AUTOSAR XML (schema 3.1.2)
package /Components/SWC_EngMGslT
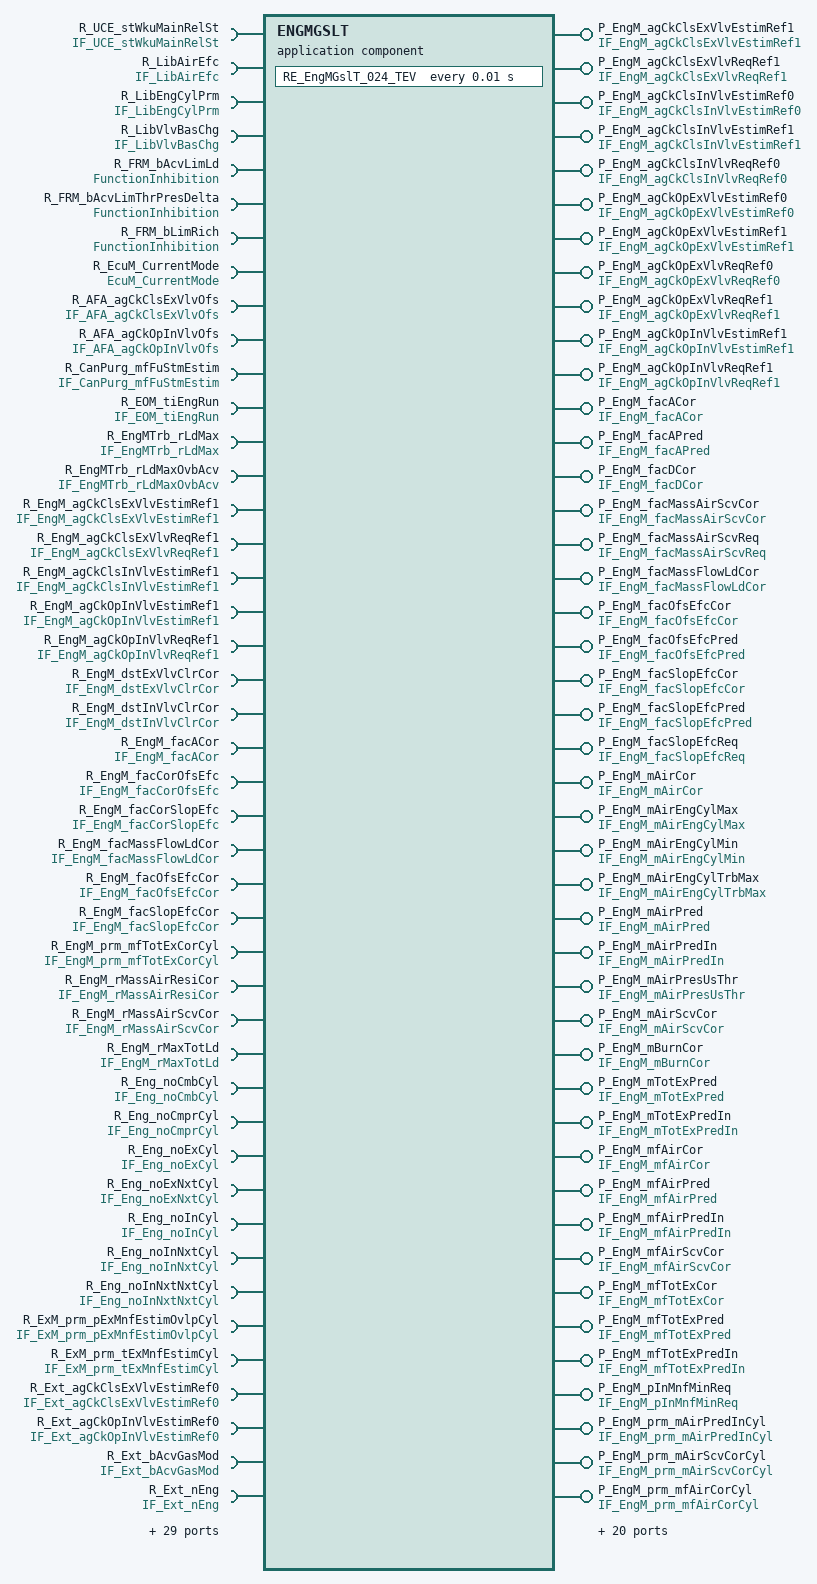
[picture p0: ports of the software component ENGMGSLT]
  application software component type ENGMGSLT  # EngMGslT
    7 x require port:
      R_UCE_stWkuMainRelSt: required-interface=IF_UCE_stWkuMainRelSt
      R_LibAirEfc: required-interface=IF_LibAirEfc
      R_LibEngCylPrm: required-interface=IF_LibEngCylPrm
      R_LibVlvBasChg: required-interface=IF_LibVlvBasChg
      R_FRM_bAcvLimLd: required-interface=FunctionInhibition
      R_FRM_bAcvLimThrPresDelta: required-interface=FunctionInhibition
      R_FRM_bLimRich: required-interface=FunctionInhibition
    63 x provide port:
      P_EngM_agCkClsExVlvEstimRef1: unqueued-sender-com-spec{data-element=EngM_agCkClsExVlvEstimRef1, can-invalidate=false, init-value=ConstantValue}, provided-interface=IF_EngM_agCkClsExVlvEstimRef1
      P_EngM_agCkClsExVlvReqRef1: unqueued-sender-com-spec{data-element=EngM_agCkClsExVlvReqRef1, can-invalidate=false, init-value=SInt16InitValue}, provided-interface=IF_EngM_agCkClsExVlvReqRef1
      P_EngM_agCkClsInVlvEstimRef0: unqueued-sender-com-spec{data-element=EngM_agCkClsInVlvEstimRef0, can-invalidate=false, init-value=UInt16InitValue}, provided-interface=IF_EngM_agCkClsInVlvEstimRef0
      P_EngM_agCkClsInVlvEstimRef1: unqueued-sender-com-spec{data-element=EngM_agCkClsInVlvEstimRef1, can-invalidate=false, init-value=ConstantValue1}, provided-interface=IF_EngM_agCkClsInVlvEstimRef1
      P_EngM_agCkClsInVlvReqRef0: unqueued-sender-com-spec{data-element=EngM_agCkClsInVlvReqRef0, can-invalidate=false, init-value=UInt8InitValue}, provided-interface=IF_EngM_agCkClsInVlvReqRef0
      P_EngM_agCkOpExVlvEstimRef0: unqueued-sender-com-spec{data-element=EngM_agCkOpExVlvEstimRef0, can-invalidate=false, init-value=UInt16InitValue3}, provided-interface=IF_EngM_agCkOpExVlvEstimRef0
      P_EngM_agCkOpExVlvEstimRef1: unqueued-sender-com-spec{data-element=EngM_agCkOpExVlvEstimRef1, can-invalidate=false, init-value=UInt16InitValue5}, provided-interface=IF_EngM_agCkOpExVlvEstimRef1
      P_EngM_agCkOpExVlvReqRef0: unqueued-sender-com-spec{data-element=EngM_agCkOpExVlvReqRef0, can-invalidate=false, init-value=UInt8InitValue7}, provided-interface=IF_EngM_agCkOpExVlvReqRef0
      P_EngM_agCkOpExVlvReqRef1: unqueued-sender-com-spec{data-element=EngM_agCkOpExVlvReqRef1, can-invalidate=false, init-value=UInt8InitValue9}, provided-interface=IF_EngM_agCkOpExVlvReqRef1
      P_EngM_agCkOpInVlvEstimRef1: unqueued-sender-com-spec{data-element=EngM_agCkOpInVlvEstimRef1, can-invalidate=false, init-value=ConstantValue11}, provided-interface=IF_EngM_agCkOpInVlvEstimRef1
      P_EngM_agCkOpInVlvReqRef1: unqueued-sender-com-spec{data-element=EngM_agCkOpInVlvReqRef1, can-invalidate=false, init-value=SInt16InitValue13}, provided-interface=IF_EngM_agCkOpInVlvReqRef1
      P_EngM_facACor: unqueued-sender-com-spec{data-element=EngM_facACor, can-invalidate=false, init-value=ConstantValue15}, provided-interface=IF_EngM_facACor
      P_EngM_facAPred: unqueued-sender-com-spec{data-element=EngM_facAPred, can-invalidate=false, init-value=UInt8InitValue17}, provided-interface=IF_EngM_facAPred
      P_EngM_facDCor: unqueued-sender-com-spec{data-element=EngM_facDCor, can-invalidate=false, init-value=UInt8InitValue19}, provided-interface=IF_EngM_facDCor
      P_EngM_facMassAirScvCor: unqueued-sender-com-spec{data-element=EngM_facMassAirScvCor, can-invalidate=false, init-value=UInt32InitValue}, provided-interface=IF_EngM_facMassAirScvCor
      P_EngM_facMassAirScvReq: unqueued-sender-com-spec{data-element=EngM_facMassAirScvReq, can-invalidate=false, init-value=UInt32InitValue21}, provided-interface=IF_EngM_facMassAirScvReq
      P_EngM_facMassFlowLdCor: unqueued-sender-com-spec{data-element=EngM_facMassFlowLdCor, can-invalidate=false, init-value=UInt16InitValue23}, provided-interface=IF_EngM_facMassFlowLdCor
      P_EngM_facOfsEfcCor: unqueued-sender-com-spec{data-element=EngM_facOfsEfcCor, can-invalidate=false, init-value=ConstantValue25}, provided-interface=IF_EngM_facOfsEfcCor
      P_EngM_facOfsEfcPred: unqueued-sender-com-spec{data-element=EngM_facOfsEfcPred, can-invalidate=false, init-value=UInt16InitValue27}, provided-interface=IF_EngM_facOfsEfcPred
      P_EngM_facSlopEfcCor: unqueued-sender-com-spec{data-element=EngM_facSlopEfcCor, can-invalidate=false, init-value=ConstantValue29}, provided-interface=IF_EngM_facSlopEfcCor
      P_EngM_facSlopEfcPred: unqueued-sender-com-spec{data-element=EngM_facSlopEfcPred, can-invalidate=false, init-value=UInt16InitValue31}, provided-interface=IF_EngM_facSlopEfcPred
      P_EngM_facSlopEfcReq: unqueued-sender-com-spec{data-element=EngM_facSlopEfcReq, can-invalidate=false, init-value=ConstantValue33}, provided-interface=IF_EngM_facSlopEfcReq
      P_EngM_mAirCor: unqueued-sender-com-spec{data-element=EngM_mAirCor, can-invalidate=false, init-value=ConstantValue35}, provided-interface=IF_EngM_mAirCor
      P_EngM_mAirEngCylMax: unqueued-sender-com-spec{data-element=EngM_mAirEngCylMax, can-invalidate=false, init-value=ConstantValue37}, provided-interface=IF_EngM_mAirEngCylMax
      P_EngM_mAirEngCylMin: unqueued-sender-com-spec{data-element=EngM_mAirEngCylMin, can-invalidate=false, init-value=ConstantValue39}, provided-interface=IF_EngM_mAirEngCylMin
      P_EngM_mAirEngCylTrbMax: unqueued-sender-com-spec{data-element=EngM_mAirEngCylTrbMax, can-invalidate=false, init-value=ConstantValue41}, provided-interface=IF_EngM_mAirEngCylTrbMax
      P_EngM_mAirPred: unqueued-sender-com-spec{data-element=EngM_mAirPred, can-invalidate=false, init-value=UInt16InitValue43}, provided-interface=IF_EngM_mAirPred
      P_EngM_mAirPredIn: unqueued-sender-com-spec{data-element=EngM_mAirPredIn, can-invalidate=false, init-value=UInt16InitValue45}, provided-interface=IF_EngM_mAirPredIn
      P_EngM_mAirPresUsThr: unqueued-sender-com-spec{data-element=EngM_mAirPresUsThr, can-invalidate=false, init-value=ConstantValue47}, provided-interface=IF_EngM_mAirPresUsThr
      P_EngM_mAirScvCor: unqueued-sender-com-spec{data-element=EngM_mAirScvCor, can-invalidate=false, init-value=UInt16InitValue49}, provided-interface=IF_EngM_mAirScvCor
      P_EngM_mBurnCor: unqueued-sender-com-spec{data-element=EngM_mBurnCor, can-invalidate=false, init-value=ConstantValue51}, provided-interface=IF_EngM_mBurnCor
      P_EngM_mTotExPred: unqueued-sender-com-spec{data-element=EngM_mTotExPred, can-invalidate=false, init-value=UInt16InitValue53}, provided-interface=IF_EngM_mTotExPred
      P_EngM_mTotExPredIn: unqueued-sender-com-spec{data-element=EngM_mTotExPredIn, can-invalidate=false, init-value=UInt16InitValue55}, provided-interface=IF_EngM_mTotExPredIn
      P_EngM_mfAirCor: unqueued-sender-com-spec{data-element=EngM_mfAirCor, can-invalidate=false, init-value=UInt16InitValue57}, provided-interface=IF_EngM_mfAirCor
      P_EngM_mfAirPred: unqueued-sender-com-spec{data-element=EngM_mfAirPred, can-invalidate=false, init-value=UInt16InitValue59}, provided-interface=IF_EngM_mfAirPred
      P_EngM_mfAirPredIn: unqueued-sender-com-spec{data-element=EngM_mfAirPredIn, can-invalidate=false, init-value=UInt16InitValue61}, provided-interface=IF_EngM_mfAirPredIn
      P_EngM_mfAirScvCor: unqueued-sender-com-spec{data-element=EngM_mfAirScvCor, can-invalidate=false, init-value=ConstantValue63}, provided-interface=IF_EngM_mfAirScvCor
      P_EngM_mfTotExCor: unqueued-sender-com-spec{data-element=EngM_mfTotExCor, can-invalidate=false, init-value=UInt16InitValue65}, provided-interface=IF_EngM_mfTotExCor
      P_EngM_mfTotExPred: unqueued-sender-com-spec{data-element=EngM_mfTotExPred, can-invalidate=false, init-value=UInt16InitValue67}, provided-interface=IF_EngM_mfTotExPred
      P_EngM_mfTotExPredIn: unqueued-sender-com-spec{data-element=EngM_mfTotExPredIn, can-invalidate=false, init-value=UInt16InitValue69}, provided-interface=IF_EngM_mfTotExPredIn
      P_EngM_pInMnfMinReq: unqueued-sender-com-spec{data-element=EngM_pInMnfMinReq, can-invalidate=false, init-value=UInt16InitValue71}, provided-interface=IF_EngM_pInMnfMinReq
      P_EngM_prm_mAirPredInCyl: unqueued-sender-com-spec{data-element=EngM_prm_mAirPredInCyl, can-invalidate=false, init-value=rt_Array_UInt16_6InitValue}, provided-interface=IF_EngM_prm_mAirPredInCyl
      P_EngM_prm_mAirScvCorCyl: unqueued-sender-com-spec{data-element=EngM_prm_mAirScvCorCyl, can-invalidate=false, init-value=rt_Array_UInt16_6InitValue73}, provided-interface=IF_EngM_prm_mAirScvCorCyl
      P_EngM_prm_mfAirCorCyl: unqueued-sender-com-spec{data-element=EngM_prm_mfAirCorCyl, can-invalidate=false, init-value=rt_Array_UInt16_6InitValue75}, provided-interface=IF_EngM_prm_mfAirCorCyl
      P_EngM_prm_mfAirPredInCyl: unqueued-sender-com-spec{data-element=EngM_prm_mfAirPredInCyl, can-invalidate=false, init-value=rt_Array_UInt16_6InitValue77}, provided-interface=IF_EngM_prm_mfAirPredInCyl
      P_EngM_prm_mfAirScvCorCyl: unqueued-sender-com-spec{data-element=EngM_prm_mfAirScvCorCyl, can-invalidate=false, init-value=rt_Array_UInt16_6InitValue79}, provided-interface=IF_EngM_prm_mfAirScvCorCyl
      P_EngM_prm_mfTotExCorCyl: unqueued-sender-com-spec{data-element=EngM_prm_mfTotExCorCyl, can-invalidate=false, init-value=rt_Array_UInt16_6InitValue81}, provided-interface=IF_EngM_prm_mfTotExCorCyl
      P_EngM_prm_rAirLdPredInCyl: unqueued-sender-com-spec{data-element=EngM_prm_rAirLdPredInCyl, can-invalidate=false, init-value=rt_Array_UInt16_6InitValue83}, provided-interface=IF_EngM_prm_rAirLdPredInCyl
      P_EngM_prm_rTotLdExCorCyl: unqueued-sender-com-spec{data-element=EngM_prm_rTotLdExCorCyl, can-invalidate=false, init-value=rt_Array_UInt16_6InitValue85}, provided-interface=IF_EngM_prm_rTotLdExCorCyl
      P_EngM_rAirLdCor: unqueued-sender-com-spec{data-element=EngM_rAirLdCor, can-invalidate=false, init-value=ConstantValue87}, provided-interface=IF_EngM_rAirLdCor
      P_EngM_rAirLdPred: unqueued-sender-com-spec{data-element=EngM_rAirLdPred, can-invalidate=false, init-value=ConstantValue89}, provided-interface=IF_EngM_rAirLdPred
      P_EngM_rAirLdPredIn: unqueued-sender-com-spec{data-element=EngM_rAirLdPredIn, can-invalidate=false, init-value=UInt16InitValue91}, provided-interface=IF_EngM_rAirLdPredIn
      P_EngM_rDeltaLdInjPha: unqueued-sender-com-spec{data-element=EngM_rDeltaLdInjPha, can-invalidate=false, init-value=ConstantValue93}, provided-interface=IF_EngM_rDeltaLdInjPha
      P_EngM_rItBurnRateCor: unqueued-sender-com-spec{data-element=EngM_rItBurnRateCor, can-invalidate=false, init-value=ConstantValue95}, provided-interface=IF_EngM_rItBurnRateCor
      P_EngM_rMassAirResiCor: unqueued-sender-com-spec{data-element=EngM_rMassAirResiCor, can-invalidate=false, init-value=ConstantValue97}, provided-interface=IF_EngM_rMassAirResiCor
      P_EngM_rMassAirScvCor: unqueued-sender-com-spec{data-element=EngM_rMassAirScvCor, can-invalidate=false, init-value=ConstantValue99}, provided-interface=IF_EngM_rMassAirScvCor
      P_EngM_rMaxTotLd: unqueued-sender-com-spec{data-element=EngM_rMaxTotLd, can-invalidate=false, init-value=ConstantValue101}, provided-interface=IF_EngM_rMaxTotLd
      P_EngM_rTotLdExCor: unqueued-sender-com-spec{data-element=EngM_rTotLdExCor, can-invalidate=false, init-value=ConstantValue103}, provided-interface=IF_EngM_rTotLdExCor
      P_EngM_rTotLdExPred: unqueued-sender-com-spec{data-element=EngM_rTotLdExPred, can-invalidate=false, init-value=UInt16InitValue105}, provided-interface=IF_EngM_rTotLdExPred
      P_EngM_rltMassAirScvCor: unqueued-sender-com-spec{data-element=EngM_rltMassAirScvCor, can-invalidate=false, init-value=ConstantValue107}, provided-interface=IF_EngM_rltMassAirScvCor
      P_EngM_tBurnCylCor: unqueued-sender-com-spec{data-element=EngM_tBurnCylCor, can-invalidate=false, init-value=UInt16InitValue109}, provided-interface=IF_EngM_tBurnCylCor
      P_EngM_tMixtCylCor: unqueued-sender-com-spec{data-element=EngM_tMixtCylCor, can-invalidate=false, init-value=ConstantValue111}, provided-interface=IF_EngM_tMixtCylCor
      P_EngM_tMixtCylGDICor: unqueued-sender-com-spec{data-element=EngM_tMixtCylGDICor, can-invalidate=false, init-value=UInt16InitValue113}, provided-interface=IF_EngM_tMixtCylGDICor
    65 x require port:
      R_EcuM_CurrentMode: required-interface=EcuM_CurrentMode
      R_AFA_agCkClsExVlvOfs: unqueued-receiver-com-spec{data-element=AFA_agCkClsExVlvOfs, init-value=ConstantValue115, resync-time=0}, required-interface=IF_AFA_agCkClsExVlvOfs
      R_AFA_agCkOpInVlvOfs: unqueued-receiver-com-spec{data-element=AFA_agCkOpInVlvOfs, init-value=ConstantValue117, resync-time=0}, required-interface=IF_AFA_agCkOpInVlvOfs
      R_CanPurg_mfFuStmEstim: unqueued-receiver-com-spec{data-element=CanPurg_mfFuStmEstim, init-value=ConstantValue119, resync-time=0}, required-interface=IF_CanPurg_mfFuStmEstim
      R_EOM_tiEngRun: unqueued-receiver-com-spec{data-element=EOM_tiEngRun, init-value=ConstantValue121, resync-time=0}, required-interface=IF_EOM_tiEngRun
      R_EngMTrb_rLdMax: unqueued-receiver-com-spec{data-element=EngMTrb_rLdMax, init-value=ConstantValue123, resync-time=0}, required-interface=IF_EngMTrb_rLdMax
      R_EngMTrb_rLdMaxOvbAcv: unqueued-receiver-com-spec{data-element=EngMTrb_rLdMaxOvbAcv, init-value=ConstantValue125, resync-time=0}, required-interface=IF_EngMTrb_rLdMaxOvbAcv
      R_EngM_agCkClsExVlvEstimRef1: unqueued-receiver-com-spec{data-element=EngM_agCkClsExVlvEstimRef1, init-value=ConstantValue, resync-time=0}, required-interface=IF_EngM_agCkClsExVlvEstimRef1
      R_EngM_agCkClsExVlvReqRef1: unqueued-receiver-com-spec{data-element=EngM_agCkClsExVlvReqRef1, init-value=SInt16InitValue, resync-time=0}, required-interface=IF_EngM_agCkClsExVlvReqRef1
      R_EngM_agCkClsInVlvEstimRef1: unqueued-receiver-com-spec{data-element=EngM_agCkClsInVlvEstimRef1, init-value=ConstantValue127, resync-time=0}, required-interface=IF_EngM_agCkClsInVlvEstimRef1
      R_EngM_agCkOpInVlvEstimRef1: unqueued-receiver-com-spec{data-element=EngM_agCkOpInVlvEstimRef1, init-value=ConstantValue129, resync-time=0}, required-interface=IF_EngM_agCkOpInVlvEstimRef1
      R_EngM_agCkOpInVlvReqRef1: unqueued-receiver-com-spec{data-element=EngM_agCkOpInVlvReqRef1, init-value=SInt16InitValue131, resync-time=0}, required-interface=IF_EngM_agCkOpInVlvReqRef1
      R_EngM_dstExVlvClrCor: unqueued-receiver-com-spec{data-element=EngM_dstExVlvClrCor, init-value=UInt16InitValue133, resync-time=0}, required-interface=IF_EngM_dstExVlvClrCor
      R_EngM_dstInVlvClrCor: unqueued-receiver-com-spec{data-element=EngM_dstInVlvClrCor, init-value=UInt16InitValue135, resync-time=0}, required-interface=IF_EngM_dstInVlvClrCor
      R_EngM_facACor: unqueued-receiver-com-spec{data-element=EngM_facACor, init-value=ConstantValue137, resync-time=0}, required-interface=IF_EngM_facACor
      R_EngM_facCorOfsEfc: unqueued-receiver-com-spec{data-element=EngM_facCorOfsEfc, init-value=SInt16InitValue139, resync-time=0}, required-interface=IF_EngM_facCorOfsEfc
      R_EngM_facCorSlopEfc: unqueued-receiver-com-spec{data-element=EngM_facCorSlopEfc, init-value=UInt16InitValue141, resync-time=0}, required-interface=IF_EngM_facCorSlopEfc
      R_EngM_facMassFlowLdCor: unqueued-receiver-com-spec{data-element=EngM_facMassFlowLdCor, init-value=UInt16InitValue143, resync-time=0}, required-interface=IF_EngM_facMassFlowLdCor
      R_EngM_facOfsEfcCor: unqueued-receiver-com-spec{data-element=EngM_facOfsEfcCor, init-value=ConstantValue145, resync-time=0}, required-interface=IF_EngM_facOfsEfcCor
      R_EngM_facSlopEfcCor: unqueued-receiver-com-spec{data-element=EngM_facSlopEfcCor, init-value=ConstantValue147, resync-time=0}, required-interface=IF_EngM_facSlopEfcCor
      R_EngM_prm_mfTotExCorCyl: unqueued-receiver-com-spec{data-element=EngM_prm_mfTotExCorCyl, init-value=rt_Array_UInt16_6InitValue149, resync-time=0}, required-interface=IF_EngM_prm_mfTotExCorCyl
      R_EngM_rMassAirResiCor: unqueued-receiver-com-spec{data-element=EngM_rMassAirResiCor, init-value=ConstantValue151, resync-time=0}, required-interface=IF_EngM_rMassAirResiCor
      R_EngM_rMassAirScvCor: unqueued-receiver-com-spec{data-element=EngM_rMassAirScvCor, init-value=ConstantValue153, resync-time=0}, required-interface=IF_EngM_rMassAirScvCor
      R_EngM_rMaxTotLd: unqueued-receiver-com-spec{data-element=EngM_rMaxTotLd, init-value=ConstantValue155, resync-time=0}, required-interface=IF_EngM_rMaxTotLd
      R_Eng_noCmbCyl: unqueued-receiver-com-spec{data-element=Eng_noCmbCyl, init-value=UInt8InitValue157, resync-time=0}, required-interface=IF_Eng_noCmbCyl
      R_Eng_noCmprCyl: unqueued-receiver-com-spec{data-element=Eng_noCmprCyl, init-value=ConstantValue159, resync-time=0}, required-interface=IF_Eng_noCmprCyl
      R_Eng_noExCyl: unqueued-receiver-com-spec{data-element=Eng_noExCyl, init-value=UInt8InitValue161, resync-time=0}, required-interface=IF_Eng_noExCyl
      R_Eng_noExNxtCyl: unqueued-receiver-com-spec{data-element=Eng_noExNxtCyl, init-value=UInt8InitValue163, resync-time=0}, required-interface=IF_Eng_noExNxtCyl
      R_Eng_noInCyl: unqueued-receiver-com-spec{data-element=Eng_noInCyl, init-value=UInt8InitValue165, resync-time=0}, required-interface=IF_Eng_noInCyl
      R_Eng_noInNxtCyl: unqueued-receiver-com-spec{data-element=Eng_noInNxtCyl, init-value=UInt8InitValue167, resync-time=0}, required-interface=IF_Eng_noInNxtCyl
      R_Eng_noInNxtNxtCyl: unqueued-receiver-com-spec{data-element=Eng_noInNxtNxtCyl, init-value=UInt8InitValue169, resync-time=0}, required-interface=IF_Eng_noInNxtNxtCyl
      R_ExM_prm_pExMnfEstimOvlpCyl: unqueued-receiver-com-spec{data-element=ExM_prm_pExMnfEstimOvlpCyl, init-value=rt_Array_UInt16_6InitValue171, resync-time=0}, required-interface=IF_ExM_prm_pExMnfEstimOvlpCyl
      R_ExM_prm_tExMnfEstimCyl: unqueued-receiver-com-spec{data-element=ExM_prm_tExMnfEstimCyl, init-value=rt_Array_UInt16_6InitValue173, resync-time=0}, required-interface=IF_ExM_prm_tExMnfEstimCyl
      R_Ext_agCkClsExVlvEstimRef0: unqueued-receiver-com-spec{data-element=Ext_agCkClsExVlvEstimRef0, init-value=ConstantValue175, resync-time=0}, required-interface=IF_Ext_agCkClsExVlvEstimRef0
      R_Ext_agCkOpInVlvEstimRef0: unqueued-receiver-com-spec{data-element=Ext_agCkOpInVlvEstimRef0, init-value=ConstantValue177, resync-time=0}, required-interface=IF_Ext_agCkOpInVlvEstimRef0
      R_Ext_bAcvGasMod: unqueued-receiver-com-spec{data-element=Ext_bAcvGasMod, init-value=BooleanInitValue, resync-time=0}, required-interface=IF_Ext_bAcvGasMod
      R_Ext_nEng: unqueued-receiver-com-spec{data-element=Ext_nEng, init-value=ConstantValue179, resync-time=0}, required-interface=IF_Ext_nEng
      R_Ext_pFuMesFineResl: unqueued-receiver-com-spec{data-element=Ext_pFuMesFineResl, init-value=UInt16InitValue181, resync-time=0}, required-interface=IF_Ext_pFuMesFineResl
      R_Ext_tCoMes: unqueued-receiver-com-spec{data-element=Ext_tCoMes, init-value=ConstantValue183, resync-time=0}, required-interface=IF_Ext_tCoMes
      R_Ext_tCoStrtMes: unqueued-receiver-com-spec{data-element=Ext_tCoStrtMes, init-value=ConstantValue185, resync-time=0}, required-interface=IF_Ext_tCoStrtMes
      R_FARSp_rMixtCylSp: unqueued-receiver-com-spec{data-element=FARSp_rMixtCylSp, init-value=ConstantValue187, resync-time=0}, required-interface=IF_FARSp_rMixtCylSp
      R_FuSysM_tFu: unqueued-receiver-com-spec{data-element=FuSysM_tFu, init-value=UInt16InitValue189, resync-time=0}, required-interface=IF_FuSysM_tFu
      R_InM_concAirCor: unqueued-receiver-com-spec{data-element=InM_concAirCor, init-value=ConstantValue191, resync-time=0}, required-interface=IF_InM_concAirCor
      R_InM_pDsThrCor: unqueued-receiver-com-spec{data-element=InM_pDsThrCor, init-value=ConstantValue193, resync-time=0}, required-interface=IF_InM_pDsThrCor
      R_InM_prm_concAirPredCyl: unqueued-receiver-com-spec{data-element=InM_prm_concAirPredCyl, init-value=rt_Array_UInt16_6InitValue195, resync-time=0}, required-interface=IF_InM_prm_concAirPredCyl
      R_InM_prm_pDsThrPredCyl: unqueued-receiver-com-spec{data-element=InM_prm_pDsThrPredCyl, init-value=rt_Array_UInt16_6InitValue197, resync-time=0}, required-interface=IF_InM_prm_pDsThrPredCyl
      R_InM_prm_pDsThrPredOvlpCyl: unqueued-receiver-com-spec{data-element=InM_prm_pDsThrPredOvlpCyl, init-value=rt_Array_UInt16_6InitValue199, resync-time=0}, required-interface=IF_InM_prm_pDsThrPredOvlpCyl
      R_InThM_tAirUsInVlvEstim: unqueued-receiver-com-spec{data-element=InThM_tAirUsInVlvEstim, init-value=ConstantValue201, resync-time=0}, required-interface=IF_InThM_tAirUsInVlvEstim
      R_InjSys_bAcvAirLdMinSat: unqueued-receiver-com-spec{data-element=InjSys_bAcvAirLdMinSat, init-value=BooleanInitValue203, resync-time=0}, required-interface=IF_InjSys_bAcvAirLdMinSat
      R_InjSys_prm_agBegInjH1ReqCyl: unqueued-receiver-com-spec{data-element=InjSys_prm_agBegInjH1ReqCyl, init-value=rt_Array_UInt16_6InitValue205, resync-time=0}, required-interface=IF_InjSys_prm_agBegInjH1ReqCyl
      R_InjSys_prm_agBegInjH2ReqCyl: unqueued-receiver-com-spec{data-element=InjSys_prm_agBegInjH2ReqCyl, init-value=rt_Array_UInt16_6InitValue207, resync-time=0}, required-interface=IF_InjSys_prm_agBegInjH2ReqCyl
      R_InjSys_prm_agEndInjH1ReqCyl: unqueued-receiver-com-spec{data-element=InjSys_prm_agEndInjH1ReqCyl, init-value=rt_Array_UInt16_6InitValue209, resync-time=0}, required-interface=IF_InjSys_prm_agEndInjH1ReqCyl
      R_InjSys_prm_agEndInjH2ReqCyl: unqueued-receiver-com-spec{data-element=InjSys_prm_agEndInjH2ReqCyl, init-value=rt_Array_UInt16_6InitValue211, resync-time=0}, required-interface=IF_InjSys_prm_agEndInjH2ReqCyl
      R_InjSys_prm_bInjCutOffCyl: unqueued-receiver-com-spec{data-element=InjSys_prm_bInjCutOffCyl, init-value=ArrayConstantValue, resync-time=0}, required-interface=IF_InjSys_prm_bInjCutOffCyl
      R_InjSys_prm_mFuInjH1ReqCyl: unqueued-receiver-com-spec{data-element=InjSys_prm_mFuInjH1ReqCyl, init-value=rt_Array_UInt16_6InitValue213, resync-time=0}, required-interface=IF_InjSys_prm_mFuInjH1ReqCyl
      R_InjSys_prm_mFuInjH2ReqCyl: unqueued-receiver-com-spec{data-element=InjSys_prm_mFuInjH2ReqCyl, init-value=rt_Array_UInt16_6InitValue215, resync-time=0}, required-interface=IF_InjSys_prm_mFuInjH2ReqCyl
      R_MPM_rLdMax: unqueued-receiver-com-spec{data-element=MPM_rLdMax, init-value=ConstantValue217, resync-time=0}, required-interface=IF_MPM_rLdMax
      R_TPM_rLdProtExThermo: unqueued-receiver-com-spec{data-element=TPM_rLdProtExThermo, init-value=ConstantValue219, resync-time=0}, required-interface=IF_TPM_rLdProtExThermo
      R_UsThrM_pAirExt: unqueued-receiver-com-spec{data-element=UsThrM_pAirExt, init-value=ConstantValue221, resync-time=0}, required-interface=IF_UsThrM_pAirExt
      R_UsThrM_pUsThrCor: unqueued-receiver-com-spec{data-element=UsThrM_pUsThrCor, init-value=ConstantValue223, resync-time=0}, required-interface=IF_UsThrM_pUsThrCor
      R_UsThrM_tThrMes: unqueued-receiver-com-spec{data-element=UsThrM_tThrMes, init-value=ConstantValue225, resync-time=0}, required-interface=IF_UsThrM_tThrMes
      R_VlvSys_agCkClsExVlvReqRef0: unqueued-receiver-com-spec{data-element=VlvSys_agCkClsExVlvReqRef0, init-value=ConstantValue227, resync-time=0}, required-interface=IF_VlvSys_agCkClsExVlvReqRef0
      R_VlvSys_agCkOpInVlvReqRef0: unqueued-receiver-com-spec{data-element=VlvSys_agCkOpInVlvReqRef0, init-value=ConstantValue229, resync-time=0}, required-interface=IF_VlvSys_agCkOpInVlvReqRef0
      R_InThM_nEngCor: unqueued-receiver-com-spec{data-element=InThM_nEngCor, init-value=ConstantValue231, resync-time=0}, required-interface=IF_InThM_nEngCor
      R_AirSys_rAirLdReq: unqueued-receiver-com-spec{data-element=AirSys_rAirLdReq, init-value=ConstantValue233, resync-time=0}, required-interface=IF_AirSys_rAirLdReq
    provide port P_EngM_facOfsEfcReq: unqueued-sender-com-spec{data-element=EngM_facOfsEfcReq, can-invalidate=false, init-value=ConstantValue2}, provided-interface=IF_EngM_facOfsEfcReq
    require port R_EngM_facOfsEfcReq: unqueued-receiver-com-spec{data-element=EngM_facOfsEfcReq, init-value=ConstantValue4, resync-time=0}, required-interface=IF_EngM_facOfsEfcReq
  163 x constant specification:
    ArrayConstantValue
      value:
        array specification ArrayConstantValue: type=rt_Array_Boolean_6_m0
          6 x boolean literal, all with type=DT_InjSys_prm_bInjCutOffCyl, value=false:
            Const
            Const{1..5}
    BooleanInitValue
      value:
        boolean literal BooleanInitValue: type=DT_Ext_bAcvGasMod, value=false
    BooleanInitValue203
      value:
        boolean literal BooleanInitValue203: type=DT_InjSys_bAcvAirLdMinSat, value=false
    ConstantValue
      value:
        integer literal ConstantValue: type=DT_EngM_agCkClsExVlvEstimRef1, value=0
    ConstantValue1
      value:
        integer literal ConstantValue1: type=DT_EngM_agCkClsInVlvEstimRef1, value=0
    ConstantValue101
      value:
        integer literal ConstantValue101: type=DT_EngM_rMaxTotLd, value=0
    ConstantValue103
      value:
        integer literal ConstantValue103: type=DT_EngM_rTotLdExCor, value=0
    ConstantValue107
      value:
        integer literal ConstantValue107: type=DT_EngM_rltMassAirScvCor, value=0
    ConstantValue11
      value:
        integer literal ConstantValue11: type=DT_EngM_agCkOpInVlvEstimRef1, value=0
    ConstantValue111
      value:
        integer literal ConstantValue111: type=DT_EngM_tMixtCylCor, value=0
    ConstantValue115
      value:
        integer literal ConstantValue115: type=DT_AFA_agCkClsExVlvOfs, value=0
    ConstantValue117
      value:
        integer literal ConstantValue117: type=DT_AFA_agCkOpInVlvOfs, value=0
    ConstantValue119
      value:
        integer literal ConstantValue119: type=DT_CanPurg_mfFuStmEstim, value=0
    ConstantValue121
      value:
        integer literal ConstantValue121: type=DT_EOM_tiEngRun, value=0
    ConstantValue123
      value:
        integer literal ConstantValue123: type=DT_EngMTrb_rLdMax, value=0
    ConstantValue125
      value:
        integer literal ConstantValue125: type=DT_EngMTrb_rLdMaxOvbAcv, value=0
    ConstantValue127
      value:
        integer literal ConstantValue127: type=DT_EngM_agCkClsInVlvEstimRef1, value=0
    ConstantValue129
      value:
        integer literal ConstantValue129: type=DT_EngM_agCkOpInVlvEstimRef1, value=0
    ConstantValue137
      value:
        integer literal ConstantValue137: type=DT_EngM_facACor, value=0
    ConstantValue145
      value:
        integer literal ConstantValue145: type=DT_EngM_facOfsEfcCor, value=0
    ConstantValue147
      value:
        integer literal ConstantValue147: type=DT_EngM_facSlopEfcCor, value=0
    ConstantValue15
      value:
        integer literal ConstantValue15: type=DT_EngM_facACor, value=0
    ConstantValue151
      value:
        integer literal ConstantValue151: type=DT_EngM_rMassAirResiCor, value=0
    ConstantValue153
      value:
        integer literal ConstantValue153: type=DT_EngM_rMassAirScvCor, value=0
    ConstantValue155
      value:
        integer literal ConstantValue155: type=DT_EngM_rMaxTotLd, value=0
    ConstantValue159
      value:
        integer literal ConstantValue159: type=DT_Eng_noCmprCyl, value=1
    ConstantValue175
      value:
        integer literal ConstantValue175: type=DT_Ext_agCkClsExVlvEstimRef0, value=-1024
    ConstantValue177
      value:
        integer literal ConstantValue177: type=DT_Ext_agCkOpInVlvEstimRef0, value=-1024
    ConstantValue179
      value:
        integer literal ConstantValue179: type=DT_Ext_nEng, value=0
    ConstantValue183
      value:
        integer literal ConstantValue183: type=DT_Ext_tCoMes, value=20
    ConstantValue185
      value:
        integer literal ConstantValue185: type=DT_Ext_tCoStrtMes, value=-40
    ConstantValue187
      value:
        integer literal ConstantValue187: type=DT_FARSp_rMixtCylSp, value=4096
    ConstantValue191
      value:
        integer literal ConstantValue191: type=DT_InM_concAirCor, value=1
    ConstantValue193
      value:
        integer literal ConstantValue193: type=DT_InM_pDsThrCor, value=0
    ConstantValue2
      value:
        integer literal ConstantValue2: type=DT_EngM_facOfsEfcReq, value=0
    ConstantValue201
      value:
        integer literal ConstantValue201: type=DT_InThM_tAirUsInVlvEstim, value=0
    ConstantValue217
      value:
        integer literal ConstantValue217: type=DT_MPM_rLdMax, value=0
    ConstantValue219
      value:
        integer literal ConstantValue219: type=DT_TPM_rLdProtExThermo, value=0
    ConstantValue221
      value:
        integer literal ConstantValue221: type=DT_UsThrM_pAirExt, value=0
    ConstantValue223
      value:
        integer literal ConstantValue223: type=DT_UsThrM_pUsThrCor, value=0
    ConstantValue225
      value:
        integer literal ConstantValue225: type=DT_UsThrM_tThrMes, value=0
    ConstantValue227
      value:
        integer literal ConstantValue227: type=DT_VlvSys_agCkClsExVlvReqRef0, value=128
    ConstantValue229
      value:
        integer literal ConstantValue229: type=DT_VlvSys_agCkOpInVlvReqRef0, value=128
    ConstantValue231
      value:
        integer literal ConstantValue231: type=DT_InThM_nEngCor, value=0
    ConstantValue233
      value:
        integer literal ConstantValue233: type=DT_AirSys_rAirLdReq, value=0
    ConstantValue25
      value:
        integer literal ConstantValue25: type=DT_EngM_facOfsEfcCor, value=0
    ConstantValue29
      value:
        integer literal ConstantValue29: type=DT_EngM_facSlopEfcCor, value=0
    ConstantValue33
      value:
        integer literal ConstantValue33: type=DT_EngM_facSlopEfcReq, value=0
    ConstantValue35
      value:
        integer literal ConstantValue35: type=DT_EngM_mAirCor, value=0
    ConstantValue37
      value:
        integer literal ConstantValue37: type=DT_EngM_mAirEngCylMax, value=0
    ConstantValue39
      value:
        integer literal ConstantValue39: type=DT_EngM_mAirEngCylMin, value=0
    ConstantValue4
      value:
        integer literal ConstantValue4: type=DT_EngM_facOfsEfcReq, value=0
    ConstantValue41
      value:
        integer literal ConstantValue41: type=DT_EngM_mAirEngCylTrbMax, value=0
    ConstantValue47
      value:
        integer literal ConstantValue47: type=DT_EngM_mAirPresUsThr, value=0
    ConstantValue51
      value:
        integer literal ConstantValue51: type=DT_EngM_mBurnCor, value=0
    ConstantValue63
      value:
        integer literal ConstantValue63: type=DT_EngM_mfAirScvCor, value=0
    ConstantValue87
      value:
        integer literal ConstantValue87: type=DT_EngM_rAirLdCor, value=0
    ConstantValue89
      value:
        integer literal ConstantValue89: type=DT_EngM_rAirLdPred, value=0
    ConstantValue93
      value:
        integer literal ConstantValue93: type=DT_EngM_rDeltaLdInjPha, value=0
    ConstantValue95
      value:
        integer literal ConstantValue95: type=DT_EngM_rItBurnRateCor, value=0
    ConstantValue97
      value:
        integer literal ConstantValue97: type=DT_EngM_rMassAirResiCor, value=0
    ConstantValue99
      value:
        integer literal ConstantValue99: type=DT_EngM_rMassAirScvCor, value=0
    rt_Array_UInt16_6InitValue
      value:
        array specification rt_Array_UInt16_6InitValue: type=rt_Array_UInt16_6_m10
          6 x integer literal, all with type=DT_EngM_prm_mAirPredInCyl, value=0:
            UInt16_{1..6}
    rt_Array_UInt16_6InitValue149
      value:
        array specification rt_Array_UInt16_6InitValue149: type=rt_Array_UInt16_6_m13
          6 x integer literal, all with type=DT_EngM_prm_mfTotExCorCyl, value=0:
            UInt16_{1..6}
    rt_Array_UInt16_6InitValue171
      value:
        array specification rt_Array_UInt16_6InitValue171: type=rt_Array_UInt16_6_m2
          6 x integer literal, all with type=DT_ExM_prm_pExMnfEstimOvlpCyl, value=0:
            UInt16_{1..6}
    rt_Array_UInt16_6InitValue173
      value:
        array specification rt_Array_UInt16_6InitValue173: type=rt_Array_UInt16_6_m1
          6 x integer literal, all with type=DT_ExM_prm_tExMnfEstimCyl, value=0:
            UInt16_{1..6}
    rt_Array_UInt16_6InitValue195
      value:
        array specification rt_Array_UInt16_6InitValue195: type=rt_Array_UInt16_6_m0
          6 x integer literal, all with type=DT_InM_prm_concAirPredCyl, value=1:
            UInt16_{1..6}
    rt_Array_UInt16_6InitValue197
      value:
        array specification rt_Array_UInt16_6InitValue197: type=rt_Array_UInt16_6_m9
          6 x integer literal, all with type=DT_InM_prm_pDsThrPredCyl, value=0:
            UInt16_{1..6}
    rt_Array_UInt16_6InitValue199
      value:
        array specification rt_Array_UInt16_6InitValue199: type=rt_Array_UInt16_6_m17
          6 x integer literal, all with type=DT_InM_prm_pDsThrPredOvlpCyl, value=0:
            UInt16_{1..6}
    rt_Array_UInt16_6InitValue205
      value:
        array specification rt_Array_UInt16_6InitValue205: type=rt_Array_UInt16_6_m3
          6 x integer literal, all with type=DT_InjSys_prm_agBegInjH1ReqCyl, value=0:
            UInt16_{1..6}
    rt_Array_UInt16_6InitValue207
      value:
        array specification rt_Array_UInt16_6InitValue207: type=rt_Array_UInt16_6_m4
          6 x integer literal, all with type=DT_InjSys_prm_agBegInjH2ReqCyl, value=0:
            UInt16_{1..6}
    rt_Array_UInt16_6InitValue209
      value:
        array specification rt_Array_UInt16_6InitValue209: type=rt_Array_UInt16_6_m18
          6 x integer literal, all with type=DT_InjSys_prm_agEndInjH1ReqCyl, value=0:
            UInt16_{1..6}
    rt_Array_UInt16_6InitValue211
      value:
        array specification rt_Array_UInt16_6InitValue211: type=rt_Array_UInt16_6_m20
          6 x integer literal, all with type=DT_InjSys_prm_agEndInjH2ReqCyl, value=0:
            UInt16_{1..6}
    rt_Array_UInt16_6InitValue213
      value:
        array specification rt_Array_UInt16_6InitValue213: type=rt_Array_UInt16_6_m19
          6 x integer literal, all with type=DT_InjSys_prm_mFuInjH1ReqCyl, value=0:
            UInt16_{1..6}
    rt_Array_UInt16_6InitValue215
      value:
        array specification rt_Array_UInt16_6InitValue215: type=rt_Array_UInt16_6_m5
          6 x integer literal, all with type=DT_InjSys_prm_mFuInjH2ReqCyl, value=0:
            UInt16_{1..6}
    rt_Array_UInt16_6InitValue73
      value:
        array specification rt_Array_UInt16_6InitValue73: type=rt_Array_UInt16_6_m11
          6 x integer literal, all with type=DT_EngM_prm_mAirScvCorCyl, value=0:
            UInt16_{1..6}
    rt_Array_UInt16_6InitValue75
      value:
        array specification rt_Array_UInt16_6InitValue75: type=rt_Array_UInt16_6_m6
          6 x integer literal, all with type=DT_EngM_prm_mfAirCorCyl, value=43:
            UInt16_{1..6}
    rt_Array_UInt16_6InitValue77
      value:
        array specification rt_Array_UInt16_6InitValue77: type=rt_Array_UInt16_6_m12
          6 x integer literal, all with type=DT_EngM_prm_mfAirPredInCyl, value=0:
            UInt16_{1..6}
    rt_Array_UInt16_6InitValue79
      value:
        array specification rt_Array_UInt16_6InitValue79: type=rt_Array_UInt16_6_m7
          6 x integer literal, all with type=DT_EngM_prm_mfAirScvCorCyl, value=0:
            UInt16_{1..6}
    rt_Array_UInt16_6InitValue81
      value:
        array specification rt_Array_UInt16_6InitValue81: type=rt_Array_UInt16_6_m13
          6 x integer literal, all with type=DT_EngM_prm_mfTotExCorCyl, value=0:
            UInt16_{1..6}
    rt_Array_UInt16_6InitValue83
      value:
        array specification rt_Array_UInt16_6InitValue83: type=rt_Array_UInt16_6_m14
          6 x integer literal, all with type=DT_EngM_prm_rAirLdPredInCyl, value=0:
            UInt16_{1..6}
    rt_Array_UInt16_6InitValue85
      value:
        array specification rt_Array_UInt16_6InitValue85: type=rt_Array_UInt16_6_m15
          6 x integer literal, all with type=DT_EngM_prm_rTotLdExCorCyl, value=0:
            UInt16_{1..6}
    SInt16InitValue
      value:
        integer literal SInt16InitValue: type=DT_EngM_agCkClsExVlvReqRef1, value=-1024
    SInt16InitValue13
      value:
        integer literal SInt16InitValue13: type=DT_EngM_agCkOpInVlvReqRef1, value=-1024
    SInt16InitValue131
      value:
        integer literal SInt16InitValue131: type=DT_EngM_agCkOpInVlvReqRef1, value=-1024
    SInt16InitValue139
      value:
        integer literal SInt16InitValue139: type=DT_EngM_facCorOfsEfc, value=0
    UInt16InitValue
      value:
        integer literal UInt16InitValue: type=DT_EngM_agCkClsInVlvEstimRef0, value=0
    UInt16InitValue105
      value:
        integer literal UInt16InitValue105: type=DT_EngM_rTotLdExPred, value=0
    UInt16InitValue109
      value:
        integer literal UInt16InitValue109: type=DT_EngM_tBurnCylCor, value=0
    UInt16InitValue113
      value:
        integer literal UInt16InitValue113: type=DT_EngM_tMixtCylGDICor, value=0
    UInt16InitValue133
      value:
        integer literal UInt16InitValue133: type=DT_EngM_dstExVlvClrCor, value=0
    UInt16InitValue135
      value:
        integer literal UInt16InitValue135: type=DT_EngM_dstInVlvClrCor, value=0
    UInt16InitValue141
      value:
        integer literal UInt16InitValue141: type=DT_EngM_facCorSlopEfc, value=32768
    UInt16InitValue143
      value:
        integer literal UInt16InitValue143: type=DT_EngM_facMassFlowLdCor, value=0
    UInt16InitValue181
      value:
        integer literal UInt16InitValue181: type=DT_Ext_pFuMesFineResl, value=0
    UInt16InitValue189
      value:
        integer literal UInt16InitValue189: type=DT_FuSysM_tFu, value=0
    UInt16InitValue23
      value:
        integer literal UInt16InitValue23: type=DT_EngM_facMassFlowLdCor, value=0
    UInt16InitValue235
      value:
        integer literal UInt16InitValue235: type=DT_EngM_facCorAtmSlopEfcPrev_irv, value=0
    UInt16InitValue237
      value:
        integer literal UInt16InitValue237: type=DT_EngM_rVolCylClsInVlvPrev_irv, value=0
    UInt16InitValue239
      value:
        integer literal UInt16InitValue239: type=DT_EngM_prm_mfAirPredCyl_004_irv, value=0
    UInt16InitValue241
      value:
        integer literal UInt16InitValue241: type=DT_EngM_prm_mfAirPredCyl_006_irv, value=0
    UInt16InitValue243
      value:
        integer literal UInt16InitValue243: type=DT_EngM_prm_mAirPredCyl_005_irv, value=0
    UInt16InitValue245
      value:
        integer literal UInt16InitValue245: type=DT_EngM_prm_mfAirPredCyl_005_irv, value=0
    UInt16InitValue249
      value:
        integer literal UInt16InitValue249: type=DT_EngM_prm_mfAirPredCyl_003_irv, value=0
    UInt16InitValue251
      value:
        integer literal UInt16InitValue251: type=DT_EngM_pBegCorBoostSlopEfcPrev_irv, value=0
    UInt16InitValue253
      value:
        integer literal UInt16InitValue253: type=DT_AirEfc_facChrExpFilPred_irv, value=0
    UInt16InitValue255
      value:
        integer literal UInt16InitValue255: type=DT_AirEfc_facChrExpScvFilReq_irv, value=0
    UInt16InitValue257
      value:
        integer literal UInt16InitValue257: type=DT_EngM_pDeltaCorSlopEfcPrev_irv, value=0
    UInt16InitValue259
      value:
        integer literal UInt16InitValue259: type=DT_EngM_prm_mAirPredCyl_004_irv, value=0
    UInt16InitValue261
      value:
        integer literal UInt16InitValue261: type=DT_EngM_rMaxAvlLd_irv, value=0
    UInt16InitValue263
      value:
        integer literal UInt16InitValue263: type=DT_AirEfc_facChrExpScvFilCor_irv, value=0
    UInt16InitValue265
      value:
        integer literal UInt16InitValue265: type=DT_EngM_prm_rAirLdPredCyl_004_irv, value=0
    UInt16InitValue267
      value:
        integer literal UInt16InitValue267: type=DT_EngM_prm_mfAirPredCyl_001_irv, value=0
    UInt16InitValue269
      value:
        integer literal UInt16InitValue269: type=DT_EngM_rMinTotLd_irv, value=0
    UInt16InitValue27
      value:
        integer literal UInt16InitValue27: type=DT_EngM_facOfsEfcPred, value=0
    UInt16InitValue271
      value:
        integer literal UInt16InitValue271: type=DT_EngM_prm_rAirLdPredCyl_003_irv, value=0
    UInt16InitValue273
      value:
        integer literal UInt16InitValue273: type=DT_EngM_prm_rAirLdPredCyl_002_irv, value=0
    UInt16InitValue275
      value:
        integer literal UInt16InitValue275: type=DT_EngM_facCorBoostSlopEfcPrev_irv, value=0
    UInt16InitValue277
      value:
        integer literal UInt16InitValue277: type=DT_EngM_prm_mfAirPredCyl_002_irv, value=0
    UInt16InitValue279
      value:
        integer literal UInt16InitValue279: type=DT_EngM_facTAirUsInVlvPrev_irv, value=0
    UInt16InitValue281
      value:
        integer literal UInt16InitValue281: type=DT_EngM_facECor_irv, value=0
    UInt16InitValue283
      value:
        integer literal UInt16InitValue283: type=DT_AirEfc_facChrExpScvFilPred_irv, value=0
    UInt16InitValue285
      value:
        integer literal UInt16InitValue285: type=DT_EngM_prm_mAirPredCyl_002_irv, value=0
    UInt16InitValue287
      value:
        integer literal UInt16InitValue287: type=DT_EngM_prm_mAirPredCyl_006_irv, value=0
    UInt16InitValue289
      value:
        integer literal UInt16InitValue289: type=DT_EngM_prm_mAirPredCyl_003_irv, value=0
    UInt16InitValue291
      value:
        integer literal UInt16InitValue291: type=DT_EngM_prm_mAirPredCyl_001_irv, value=0
    UInt16InitValue293
      value:
        integer literal UInt16InitValue293: type=DT_AirEfc_facChrExpFilReq_irv, value=0
    UInt16InitValue295
      value:
        integer literal UInt16InitValue295: type=DT_InM_pDsThrPrev_irv, value=0
    UInt16InitValue297
      value:
        integer literal UInt16InitValue297: type=DT_EngM_prm_rAirLdPredCyl_005_irv, value=0
    UInt16InitValue299
      value:
        integer literal UInt16InitValue299: type=DT_EngM_prm_rAirLdPredCyl_001_irv, value=0
    UInt16InitValue3
      value:
        integer literal UInt16InitValue3: type=DT_EngM_agCkOpExVlvEstimRef0, value=0
    UInt16InitValue301
      value:
        integer literal UInt16InitValue301: type=DT_AirEfc_facChrExpFilCor_irv, value=0
    UInt16InitValue305
      value:
        integer literal UInt16InitValue305: type=DT_EngM_prm_rAirLdPredCyl_006_irv, value=0
    UInt16InitValue31
      value:
        integer literal UInt16InitValue31: type=DT_EngM_facSlopEfcPred, value=0
    UInt16InitValue43
      value:
        integer literal UInt16InitValue43: type=DT_EngM_mAirPred, value=0
    UInt16InitValue45
      value:
        integer literal UInt16InitValue45: type=DT_EngM_mAirPredIn, value=0
    UInt16InitValue49
      value:
        integer literal UInt16InitValue49: type=DT_EngM_mAirScvCor, value=0
    UInt16InitValue5
      value:
        integer literal UInt16InitValue5: type=DT_EngM_agCkOpExVlvEstimRef1, value=0
    UInt16InitValue53
      value:
        integer literal UInt16InitValue53: type=DT_EngM_mTotExPred, value=0
    UInt16InitValue55
      value:
        integer literal UInt16InitValue55: type=DT_EngM_mTotExPredIn, value=0
    UInt16InitValue57
      value:
        integer literal UInt16InitValue57: type=DT_EngM_mfAirCor, value=0
    UInt16InitValue59
      value:
        integer literal UInt16InitValue59: type=DT_EngM_mfAirPred, value=0
    UInt16InitValue61
      value:
        integer literal UInt16InitValue61: type=DT_EngM_mfAirPredIn, value=393
    UInt16InitValue65
      value:
        integer literal UInt16InitValue65: type=DT_EngM_mfTotExCor, value=0
    UInt16InitValue67
      value:
        integer literal UInt16InitValue67: type=DT_EngM_mfTotExPred, value=0
    UInt16InitValue69
      value:
        integer literal UInt16InitValue69: type=DT_EngM_mfTotExPredIn, value=0
    UInt16InitValue71
      value:
        integer literal UInt16InitValue71: type=DT_EngM_pInMnfMinReq, value=0
    UInt16InitValue91
      value:
        integer literal UInt16InitValue91: type=DT_EngM_rAirLdPredIn, value=0
    UInt32InitValue
      value:
        integer literal UInt32InitValue: type=DT_EngM_facMassAirScvCor, value=0
    UInt32InitValue21
      value:
        integer literal UInt32InitValue21: type=DT_EngM_facMassAirScvReq, value=0
    UInt8InitValue
      value:
        integer literal UInt8InitValue: type=DT_EngM_agCkClsInVlvReqRef0, value=0
    UInt8InitValue157
      value:
        integer literal UInt8InitValue157: type=DT_Eng_noCmbCyl, value=1
    UInt8InitValue161
      value:
        integer literal UInt8InitValue161: type=DT_Eng_noExCyl, value=1
    UInt8InitValue163
      value:
        integer literal UInt8InitValue163: type=DT_Eng_noExNxtCyl, value=1
    UInt8InitValue165
      value:
        integer literal UInt8InitValue165: type=DT_Eng_noInCyl, value=1
    UInt8InitValue167
      value:
        integer literal UInt8InitValue167: type=DT_Eng_noInNxtCyl, value=1
    UInt8InitValue169
      value:
        integer literal UInt8InitValue169: type=DT_Eng_noInNxtNxtCyl, value=1
    UInt8InitValue17
      value:
        integer literal UInt8InitValue17: type=DT_EngM_facAPred, value=0
    UInt8InitValue19
      value:
        integer literal UInt8InitValue19: type=DT_EngM_facDCor, value=0
    UInt8InitValue247
      value:
        integer literal UInt8InitValue247: type=DT_EngM_facTCoPrev_irv, value=0
    UInt8InitValue303
      value:
        integer literal UInt8InitValue303: type=DT_EngM_agCkClsInVlvReqRef1_irv, value=0
    UInt8InitValue7
      value:
        integer literal UInt8InitValue7: type=DT_EngM_agCkOpExVlvReqRef0, value=0
    UInt8InitValue9
      value:
        integer literal UInt8InitValue9: type=DT_EngM_agCkOpExVlvReqRef1, value=0
  internal behavior IB_EngMGslT: component=ENGMGSLT
    timing event EV_EngMGslT_024_TEV: mode-dependency=dependent-on-mode=[R_UCE_stWkuMainRelSt.RCD_stWkuMainRelSt.PreMainWakeUp, R_UCE_stWkuMainRelSt.RCD_stWkuMainRelSt.PostMainWakeUp, R_UCE_stWkuMainRelSt.RCD_stWkuMainRelSt.Invalid], start-on-event=RE_EngMGslT_024_TEV, period=0.01
    mode switch event EV_EngMGslT_001_MSE: start-on-event=RE_EngMGslT_001_MSE, activation=ENTRY, mode=R_EcuM_CurrentMode.currentMode.RUN
    8 x timing event, all with mode-dependency=dependent-on-mode=[R_UCE_stWkuMainRelSt.RCD_stWkuMainRelSt.PreMainWakeUp, R_UCE_stWkuMainRelSt.RCD_stWkuMainRelSt.PostMainWakeUp, R_UCE_stWkuMainRelSt.RCD_stWkuMainRelSt.Invalid]:
      EV_EngMGslT_026_TEV: start-on-event=RE_EngMGslT_026_TEV, period=0.01
      EV_EngMGslT_012_TEV: start-on-event=RE_EngMGslT_012_TEV, period=0.005
      EV_EngMGslT_018_TEV: start-on-event=RE_EngMGslT_018_TEV, period=0.01
      EV_EngMGslT_002_TEV: start-on-event=RE_EngMGslT_002_TEV, period=0.01
      EV_EngMGslT_022_TEV: start-on-event=RE_EngMGslT_022_TEV, period=0.01
      EV_EngMGslT_020_TEV: start-on-event=RE_EngMGslT_020_TEV, period=0.005
      EV_EngMGslT_004_TEV: start-on-event=RE_EngMGslT_004_TEV, period=0.01
      EV_EngMGslT_008_TEV: start-on-event=RE_EngMGslT_008_TEV, period=0.005
    36 x inter runnable variable, all with sw-calibration-access=READ-WRITE, communication-approach=EXPLICIT:
      EngM_prm_rAirLdPredCyl_006_irv: type=DT_EngM_prm_rAirLdPredCyl_006_irv, init-value=UInt16InitValue305
      EngM_prm_rAirLdPredCyl_004_irv: type=DT_EngM_prm_rAirLdPredCyl_004_irv, init-value=UInt16InitValue265
      EngM_agCkClsInVlvReqRef1_irv: type=DT_EngM_agCkClsInVlvReqRef1_irv, init-value=UInt8InitValue303
      EngM_rMinTotLd_irv: type=DT_EngM_rMinTotLd_irv, init-value=UInt16InitValue269
      AirEfc_facChrExpFilPred_irv: type=DT_AirEfc_facChrExpFilPred_irv, init-value=UInt16InitValue253
      EngM_prm_mAirPredCyl_005_irv: type=DT_EngM_prm_mAirPredCyl_005_irv, init-value=UInt16InitValue243
      AirEfc_facChrExpFilReq_irv: type=DT_AirEfc_facChrExpFilReq_irv, init-value=UInt16InitValue293
      EngM_pBegCorBoostSlopEfcPrev_irv: type=DT_EngM_pBegCorBoostSlopEfcPrev_irv, init-value=UInt16InitValue251
      EngM_prm_mAirPredCyl_001_irv: type=DT_EngM_prm_mAirPredCyl_001_irv, init-value=UInt16InitValue291
      EngM_facCorAtmSlopEfcPrev_irv: type=DT_EngM_facCorAtmSlopEfcPrev_irv, init-value=UInt16InitValue235
      EngM_pDeltaCorSlopEfcPrev_irv: type=DT_EngM_pDeltaCorSlopEfcPrev_irv, init-value=UInt16InitValue257
      AirEfc_facChrExpScvFilPred_irv: type=DT_AirEfc_facChrExpScvFilPred_irv, init-value=UInt16InitValue283
      EngM_prm_mfAirPredCyl_004_irv: type=DT_EngM_prm_mfAirPredCyl_004_irv, init-value=UInt16InitValue239
      EngM_prm_rAirLdPredCyl_005_irv: type=DT_EngM_prm_rAirLdPredCyl_005_irv, init-value=UInt16InitValue297
      EngM_facCorBoostSlopEfcPrev_irv: type=DT_EngM_facCorBoostSlopEfcPrev_irv, init-value=UInt16InitValue275
      EngM_prm_rAirLdPredCyl_001_irv: type=DT_EngM_prm_rAirLdPredCyl_001_irv, init-value=UInt16InitValue299
      EngM_prm_mAirPredCyl_002_irv: type=DT_EngM_prm_mAirPredCyl_002_irv, init-value=UInt16InitValue285
      EngM_prm_mfAirPredCyl_006_irv: type=DT_EngM_prm_mfAirPredCyl_006_irv, init-value=UInt16InitValue241
      EngM_facECor_irv: type=DT_EngM_facECor_irv, init-value=UInt16InitValue281
      EngM_rVolCylClsInVlvPrev_irv: type=DT_EngM_rVolCylClsInVlvPrev_irv, init-value=UInt16InitValue237
      EngM_prm_mAirPredCyl_004_irv: type=DT_EngM_prm_mAirPredCyl_004_irv, init-value=UInt16InitValue259
      EngM_prm_mAirPredCyl_006_irv: type=DT_EngM_prm_mAirPredCyl_006_irv, init-value=UInt16InitValue287
      AirEfc_facChrExpScvFilReq_irv: type=DT_AirEfc_facChrExpScvFilReq_irv, init-value=UInt16InitValue255
      AirEfc_facChrExpScvFilCor_irv: type=DT_AirEfc_facChrExpScvFilCor_irv, init-value=UInt16InitValue263
      AirEfc_facChrExpFilCor_irv: type=DT_AirEfc_facChrExpFilCor_irv, init-value=UInt16InitValue301
      EngM_prm_mfAirPredCyl_001_irv: type=DT_EngM_prm_mfAirPredCyl_001_irv, init-value=UInt16InitValue267
      EngM_prm_mfAirPredCyl_005_irv: type=DT_EngM_prm_mfAirPredCyl_005_irv, init-value=UInt16InitValue245
      EngM_prm_mAirPredCyl_003_irv: type=DT_EngM_prm_mAirPredCyl_003_irv, init-value=UInt16InitValue289
      EngM_prm_mfAirPredCyl_003_irv: type=DT_EngM_prm_mfAirPredCyl_003_irv, init-value=UInt16InitValue249
      EngM_prm_rAirLdPredCyl_003_irv: type=DT_EngM_prm_rAirLdPredCyl_003_irv, init-value=UInt16InitValue271
      EngM_facTCoPrev_irv: type=DT_EngM_facTCoPrev_irv, init-value=UInt8InitValue247
      EngM_prm_mfAirPredCyl_002_irv: type=DT_EngM_prm_mfAirPredCyl_002_irv, init-value=UInt16InitValue277
      EngM_rMaxAvlLd_irv: type=DT_EngM_rMaxAvlLd_irv, init-value=UInt16InitValue261
      InM_pDsThrPrev_irv: type=DT_InM_pDsThrPrev_irv, init-value=UInt16InitValue295
      EngM_prm_rAirLdPredCyl_002_irv: type=DT_EngM_prm_rAirLdPredCyl_002_irv, init-value=UInt16InitValue273
      EngM_facTAirUsInVlvPrev_irv: type=DT_EngM_facTAirUsInVlvPrev_irv, init-value=UInt16InitValue279
    10 x runnable:
      RE_EngMGslT_018_TEV: read-variable=[AirEfc_facChrExpFilCor_irv, AirEfc_facChrExpScvFilCor_irv], written-variable=[AirEfc_facChrExpFilCor_irv, EngM_facECor_irv, AirEfc_facChrExpScvFilCor_irv]
        30 x data receive point:
          dr_InjSys_prm_agBegInjH2ReqCyl: data-element=R_InjSys_prm_agBegInjH2ReqCyl.InjSys_prm_agBegInjH2ReqCyl
          dr_InThM_tAirUsInVlvEstim: data-element=R_InThM_tAirUsInVlvEstim.InThM_tAirUsInVlvEstim
          dr_ExM_prm_pExMnfEstimOvlpCyl: data-element=R_ExM_prm_pExMnfEstimOvlpCyl.ExM_prm_pExMnfEstimOvlpCyl
          dr_EngM_agCkClsExVlvEstimRef1: data-element=R_EngM_agCkClsExVlvEstimRef1.EngM_agCkClsExVlvEstimRef1
          dr_Eng_noCmprCyl: data-element=R_Eng_noCmprCyl.Eng_noCmprCyl
          dr_EngM_facCorOfsEfc: data-element=R_EngM_facCorOfsEfc.EngM_facCorOfsEfc
          dr_EngM_prm_mfTotExCorCyl: data-element=R_EngM_prm_mfTotExCorCyl.EngM_prm_mfTotExCorCyl
          dr_Eng_noCmbCyl: data-element=R_Eng_noCmbCyl.Eng_noCmbCyl
          dr_Ext_tCoMes: data-element=R_Ext_tCoMes.Ext_tCoMes
          dr_UsThrM_pAirExt: data-element=R_UsThrM_pAirExt.UsThrM_pAirExt
          dr_Eng_noExCyl: data-element=R_Eng_noExCyl.Eng_noExCyl
          dr_InjSys_prm_mFuInjH2ReqCyl: data-element=R_InjSys_prm_mFuInjH2ReqCyl.InjSys_prm_mFuInjH2ReqCyl
          dr_EngM_agCkOpInVlvEstimRef1: data-element=R_EngM_agCkOpInVlvEstimRef1.EngM_agCkOpInVlvEstimRef1
          dr_Eng_noInCyl: data-element=R_Eng_noInCyl.Eng_noInCyl
          dr_Eng_noInNxtNxtCyl: data-element=R_Eng_noInNxtNxtCyl.Eng_noInNxtNxtCyl
          dr_FARSp_rMixtCylSp: data-element=R_FARSp_rMixtCylSp.FARSp_rMixtCylSp
          dr_InjSys_prm_mFuInjH1ReqCyl: data-element=R_InjSys_prm_mFuInjH1ReqCyl.InjSys_prm_mFuInjH1ReqCyl
          dr_EngM_facCorSlopEfc: data-element=R_EngM_facCorSlopEfc.EngM_facCorSlopEfc
          dr_EngM_agCkClsInVlvEstimRef1: data-element=R_EngM_agCkClsInVlvEstimRef1.EngM_agCkClsInVlvEstimRef1
          dr_Ext_nEng: data-element=R_Ext_nEng.Ext_nEng
          dr_InM_pDsThrCor: data-element=R_InM_pDsThrCor.InM_pDsThrCor
          dr_ExM_prm_tExMnfEstimCyl: data-element=R_ExM_prm_tExMnfEstimCyl.ExM_prm_tExMnfEstimCyl
          dr_InjSys_prm_agEndInjH1ReqCyl: data-element=R_InjSys_prm_agEndInjH1ReqCyl.InjSys_prm_agEndInjH1ReqCyl
          dr_InM_concAirCor: data-element=R_InM_concAirCor.InM_concAirCor
          dr_InM_prm_pDsThrPredOvlpCyl: data-element=R_InM_prm_pDsThrPredOvlpCyl.InM_prm_pDsThrPredOvlpCyl
          dr_FuSysM_tFu: data-element=R_FuSysM_tFu.FuSysM_tFu
          dr_Eng_noInNxtCyl: data-element=R_Eng_noInNxtCyl.Eng_noInNxtCyl
          dr_InjSys_prm_agEndInjH2ReqCyl: data-element=R_InjSys_prm_agEndInjH2ReqCyl.InjSys_prm_agEndInjH2ReqCyl
          dr_InThM_nEngCor: data-element=R_InThM_nEngCor.InThM_nEngCor
          dr_InjSys_prm_agBegInjH1ReqCyl: data-element=R_InjSys_prm_agBegInjH1ReqCyl.InjSys_prm_agBegInjH1ReqCyl
        27 x data send point:
          ds_EngM_facDCor: data-element=P_EngM_facDCor.EngM_facDCor
          ds_EngM_mAirCor: data-element=P_EngM_mAirCor.EngM_mAirCor
          ds_EngM_mfTotExCor: data-element=P_EngM_mfTotExCor.EngM_mfTotExCor
          ds_EngM_mfAirScvCor: data-element=P_EngM_mfAirScvCor.EngM_mfAirScvCor
          ds_EngM_mfAirCor: data-element=P_EngM_mfAirCor.EngM_mfAirCor
          ds_EngM_facSlopEfcCor: data-element=P_EngM_facSlopEfcCor.EngM_facSlopEfcCor
          ds_EngM_rDeltaLdInjPha: data-element=P_EngM_rDeltaLdInjPha.EngM_rDeltaLdInjPha
          ds_EngM_facOfsEfcCor: data-element=P_EngM_facOfsEfcCor.EngM_facOfsEfcCor
          ds_EngM_rMassAirResiCor: data-element=P_EngM_rMassAirResiCor.EngM_rMassAirResiCor
          ds_EngM_rTotLdExCor: data-element=P_EngM_rTotLdExCor.EngM_rTotLdExCor
          ds_EngM_rItBurnRateCor: data-element=P_EngM_rItBurnRateCor.EngM_rItBurnRateCor
          ds_EngM_prm_mfAirCorCyl: data-element=P_EngM_prm_mfAirCorCyl.EngM_prm_mfAirCorCyl
          ds_EngM_mAirScvCor: data-element=P_EngM_mAirScvCor.EngM_mAirScvCor
          ds_EngM_tBurnCylCor: data-element=P_EngM_tBurnCylCor.EngM_tBurnCylCor
          ds_EngM_rltMassAirScvCor: data-element=P_EngM_rltMassAirScvCor.EngM_rltMassAirScvCor
          ds_EngM_prm_rTotLdExCorCyl: data-element=P_EngM_prm_rTotLdExCorCyl.EngM_prm_rTotLdExCorCyl
          ds_EngM_facMassFlowLdCor: data-element=P_EngM_facMassFlowLdCor.EngM_facMassFlowLdCor
          ds_EngM_tMixtCylCor: data-element=P_EngM_tMixtCylCor.EngM_tMixtCylCor
          ds_EngM_rAirLdCor: data-element=P_EngM_rAirLdCor.EngM_rAirLdCor
          ds_EngM_prm_mfTotExCorCyl: data-element=P_EngM_prm_mfTotExCorCyl.EngM_prm_mfTotExCorCyl
          ds_EngM_rMassAirScvCor: data-element=P_EngM_rMassAirScvCor.EngM_rMassAirScvCor
          ds_EngM_mBurnCor: data-element=P_EngM_mBurnCor.EngM_mBurnCor
          ds_EngM_facACor: data-element=P_EngM_facACor.EngM_facACor
          ds_EngM_tMixtCylGDICor: data-element=P_EngM_tMixtCylGDICor.EngM_tMixtCylGDICor
          ds_EngM_prm_mfAirScvCorCyl: data-element=P_EngM_prm_mfAirScvCorCyl.EngM_prm_mfAirScvCorCyl
          ds_EngM_facMassAirScvCor: data-element=P_EngM_facMassAirScvCor.EngM_facMassAirScvCor
          ds_EngM_prm_mAirScvCorCyl: data-element=P_EngM_prm_mAirScvCorCyl.EngM_prm_mAirScvCorCyl
        sync call ssp_LibEngCylPrm: operation=R_LibEngCylPrm.OP_LibEngCylPrm
        sync call ssp_LibAirEfc: operation=R_LibAirEfc.OP_LibAirEfc
      RE_EngMGslT_024_TEV: written-variable=EngM_rMaxAvlLd_irv
        13 x data receive point:
          dr_Ext_bAcvGasMod: data-element=R_Ext_bAcvGasMod.Ext_bAcvGasMod
          dr_EngM_facACor: data-element=R_EngM_facACor.EngM_facACor
          dr_EngMTrb_rLdMax: data-element=R_EngMTrb_rLdMax.EngMTrb_rLdMax
          dr_UsThrM_pUsThrCor: data-element=R_UsThrM_pUsThrCor.UsThrM_pUsThrCor
          dr_TPM_rLdProtExThermo: data-element=R_TPM_rLdProtExThermo.TPM_rLdProtExThermo
          dr_EngM_facSlopEfcCor: data-element=R_EngM_facSlopEfcCor.EngM_facSlopEfcCor
          dr_Ext_tCoMes: data-element=R_Ext_tCoMes.Ext_tCoMes
          dr_UsThrM_tThrMes: data-element=R_UsThrM_tThrMes.UsThrM_tThrMes
          dr_Ext_nEng: data-element=R_Ext_nEng.Ext_nEng
          dr_EngM_facOfsEfcCor: data-element=R_EngM_facOfsEfcCor.EngM_facOfsEfcCor
          dr_InM_concAirCor: data-element=R_InM_concAirCor.InM_concAirCor
          dr_MPM_rLdMax: data-element=R_MPM_rLdMax.MPM_rLdMax
          dr_UsThrM_pAirExt: data-element=R_UsThrM_pAirExt.UsThrM_pAirExt
        data send point ds_EngM_rMaxTotLd: data-element=P_EngM_rMaxTotLd.EngM_rMaxTotLd
        sync call ssp_FRM_bAcvLimLd: operation=R_FRM_bAcvLimLd.GetFunctionPermission
        sync call ssp_FRM_bLimRich: operation=R_FRM_bLimRich.GetFunctionPermission
        sync call ssp_FRM_bAcvLimThrPresDelta: operation=R_FRM_bAcvLimThrPresDelta.GetFunctionPermission
      RE_EngMGslT_012_TEV
        8 x data receive point:
          dr_AFA_agCkClsExVlvOfs: data-element=R_AFA_agCkClsExVlvOfs.AFA_agCkClsExVlvOfs
          dr_EOM_tiEngRun: data-element=R_EOM_tiEngRun.EOM_tiEngRun
          dr_Ext_agCkOpInVlvEstimRef0: data-element=R_Ext_agCkOpInVlvEstimRef0.Ext_agCkOpInVlvEstimRef0
          dr_AFA_agCkOpInVlvOfs: data-element=R_AFA_agCkOpInVlvOfs.AFA_agCkOpInVlvOfs
          dr_EngM_dstExVlvClrCor: data-element=R_EngM_dstExVlvClrCor.EngM_dstExVlvClrCor
          dr_Ext_agCkClsExVlvEstimRef0: data-element=R_Ext_agCkClsExVlvEstimRef0.Ext_agCkClsExVlvEstimRef0
          dr_Ext_tCoStrtMes: data-element=R_Ext_tCoStrtMes.Ext_tCoStrtMes
          dr_EngM_dstInVlvClrCor: data-element=R_EngM_dstInVlvClrCor.EngM_dstInVlvClrCor
        6 x data send point:
          ds_EngM_agCkOpExVlvEstimRef0: data-element=P_EngM_agCkOpExVlvEstimRef0.EngM_agCkOpExVlvEstimRef0
          ds_EngM_agCkClsInVlvEstimRef0: data-element=P_EngM_agCkClsInVlvEstimRef0.EngM_agCkClsInVlvEstimRef0
          ds_EngM_agCkOpInVlvEstimRef1: data-element=P_EngM_agCkOpInVlvEstimRef1.EngM_agCkOpInVlvEstimRef1
          ds_EngM_agCkOpExVlvEstimRef1: data-element=P_EngM_agCkOpExVlvEstimRef1.EngM_agCkOpExVlvEstimRef1
          ds_EngM_agCkClsInVlvEstimRef1: data-element=P_EngM_agCkClsInVlvEstimRef1.EngM_agCkClsInVlvEstimRef1
          ds_EngM_agCkClsExVlvEstimRef1: data-element=P_EngM_agCkClsExVlvEstimRef1.EngM_agCkClsExVlvEstimRef1
        sync call ssp_LibVlvBasChg: operation=R_LibVlvBasChg.OP_LibVlvBasChg
      RE_EngMGslT_004_TEV: read-variable=[EngM_rMaxAvlLd_irv, EngM_rMinTotLd_irv]
        data receive point dr_EngMTrb_rLdMaxOvbAcv: data-element=R_EngMTrb_rLdMaxOvbAcv.EngMTrb_rLdMaxOvbAcv
        data receive point dr_EngM_rMaxTotLd: data-element=R_EngM_rMaxTotLd.EngM_rMaxTotLd
        4 x data send point:
          ds_EngM_mAirPresUsThr: data-element=P_EngM_mAirPresUsThr.EngM_mAirPresUsThr
          ds_EngM_mAirEngCylMin: data-element=P_EngM_mAirEngCylMin.EngM_mAirEngCylMin
          ds_EngM_mAirEngCylMax: data-element=P_EngM_mAirEngCylMax.EngM_mAirEngCylMax
          ds_EngM_mAirEngCylTrbMax: data-element=P_EngM_mAirEngCylTrbMax.EngM_mAirEngCylTrbMax
      RE_EngMGslT_022_TEV: read-variable=[EngM_pDeltaCorSlopEfcPrev_irv, EngM_pBegCorBoostSlopEfcPrev_irv, InM_pDsThrPrev_irv, EngM_facTCoPrev_irv, EngM_facCorAtmSlopEfcPrev_irv, EngM_facTAirUsInVlvPrev_irv, EngM_agCkClsInVlvReqRef1_irv, EngM_facCorBoostSlopEfcPrev_irv, EngM_rVolCylClsInVlvPrev_irv, AirEfc_facChrExpFilReq_irv, AirEfc_facChrExpScvFilReq_irv], written-variable=[EngM_pDeltaCorSlopEfcPrev_irv, EngM_pBegCorBoostSlopEfcPrev_irv, InM_pDsThrPrev_irv, EngM_facTCoPrev_irv, EngM_facCorAtmSlopEfcPrev_irv, EngM_facTAirUsInVlvPrev_irv, EngM_facCorBoostSlopEfcPrev_irv, EngM_rVolCylClsInVlvPrev_irv, AirEfc_facChrExpFilReq_irv, AirEfc_facChrExpScvFilReq_irv]
        28 x data receive point:
          dr_FARSp_rMixtCylSp: data-element=R_FARSp_rMixtCylSp.FARSp_rMixtCylSp
          dr_InjSys_prm_mFuInjH2ReqCyl: data-element=R_InjSys_prm_mFuInjH2ReqCyl.InjSys_prm_mFuInjH2ReqCyl
          dr_EngM_agCkClsExVlvReqRef1: data-element=R_EngM_agCkClsExVlvReqRef1.EngM_agCkClsExVlvReqRef1
          dr_InThM_nEngCor: data-element=R_InThM_nEngCor.InThM_nEngCor
          dr_ExM_prm_pExMnfEstimOvlpCyl: data-element=R_ExM_prm_pExMnfEstimOvlpCyl.ExM_prm_pExMnfEstimOvlpCyl
          dr_EngM_facCorSlopEfc: data-element=R_EngM_facCorSlopEfc.EngM_facCorSlopEfc
          dr_InM_concAirCor: data-element=R_InM_concAirCor.InM_concAirCor
          dr_Ext_nEng: data-element=R_Ext_nEng.Ext_nEng
          dr_InjSys_prm_agBegInjH2ReqCyl: data-element=R_InjSys_prm_agBegInjH2ReqCyl.InjSys_prm_agBegInjH2ReqCyl
          dr_Eng_noExCyl: data-element=R_Eng_noExCyl.Eng_noExCyl
          dr_InM_prm_pDsThrPredOvlpCyl: data-element=R_InM_prm_pDsThrPredOvlpCyl.InM_prm_pDsThrPredOvlpCyl
          dr_Eng_noCmbCyl: data-element=R_Eng_noCmbCyl.Eng_noCmbCyl
          dr_Ext_tCoMes: data-element=R_Ext_tCoMes.Ext_tCoMes
          dr_InjSys_prm_agEndInjH2ReqCyl: data-element=R_InjSys_prm_agEndInjH2ReqCyl.InjSys_prm_agEndInjH2ReqCyl
          dr_InjSys_prm_mFuInjH1ReqCyl: data-element=R_InjSys_prm_mFuInjH1ReqCyl.InjSys_prm_mFuInjH1ReqCyl
          dr_FuSysM_tFu: data-element=R_FuSysM_tFu.FuSysM_tFu
          dr_AirSys_rAirLdReq: data-element=R_AirSys_rAirLdReq.AirSys_rAirLdReq
          dr_InM_pDsThrCor: data-element=R_InM_pDsThrCor.InM_pDsThrCor
          dr_UsThrM_pAirExt: data-element=R_UsThrM_pAirExt.UsThrM_pAirExt
          dr_EngM_agCkOpInVlvReqRef1: data-element=R_EngM_agCkOpInVlvReqRef1.EngM_agCkOpInVlvReqRef1
          dr_Eng_noCmprCyl: data-element=R_Eng_noCmprCyl.Eng_noCmprCyl
          dr_InjSys_prm_agBegInjH1ReqCyl: data-element=R_InjSys_prm_agBegInjH1ReqCyl.InjSys_prm_agBegInjH1ReqCyl
          dr_ExM_prm_tExMnfEstimCyl: data-element=R_ExM_prm_tExMnfEstimCyl.ExM_prm_tExMnfEstimCyl
          dr_Eng_noInCyl: data-element=R_Eng_noInCyl.Eng_noInCyl
          dr_InThM_tAirUsInVlvEstim: data-element=R_InThM_tAirUsInVlvEstim.InThM_tAirUsInVlvEstim
          dr_EngM_facOfsEfcReq: data-element=R_EngM_facOfsEfcReq.EngM_facOfsEfcReq
          dr_InjSys_prm_agEndInjH1ReqCyl: data-element=R_InjSys_prm_agEndInjH1ReqCyl.InjSys_prm_agEndInjH1ReqCyl
          dr_EngM_facCorOfsEfc: data-element=R_EngM_facCorOfsEfc.EngM_facCorOfsEfc
        data send point ds_EngM_facOfsEfcReq: data-element=P_EngM_facOfsEfcReq.EngM_facOfsEfcReq
        data send point ds_EngM_facMassAirScvReq: data-element=P_EngM_facMassAirScvReq.EngM_facMassAirScvReq
        data send point ds_EngM_facSlopEfcReq: data-element=P_EngM_facSlopEfcReq.EngM_facSlopEfcReq
        sync call ssp_LibEngCylPrm: operation=R_LibEngCylPrm.OP_LibEngCylPrm
        sync call ssp_LibAirEfc: operation=R_LibAirEfc.OP_LibAirEfc
      RE_EngMGslT_008_TEV: written-variable=EngM_agCkClsInVlvReqRef1_irv
        8 x data receive point:
          dr_Ext_tCoStrtMes: data-element=R_Ext_tCoStrtMes.Ext_tCoStrtMes
          dr_EngM_dstExVlvClrCor: data-element=R_EngM_dstExVlvClrCor.EngM_dstExVlvClrCor
          dr_AFA_agCkClsExVlvOfs: data-element=R_AFA_agCkClsExVlvOfs.AFA_agCkClsExVlvOfs
          dr_EngM_dstInVlvClrCor: data-element=R_EngM_dstInVlvClrCor.EngM_dstInVlvClrCor
          dr_VlvSys_agCkClsExVlvReqRef0: data-element=R_VlvSys_agCkClsExVlvReqRef0.VlvSys_agCkClsExVlvReqRef0
          dr_AFA_agCkOpInVlvOfs: data-element=R_AFA_agCkOpInVlvOfs.AFA_agCkOpInVlvOfs
          dr_EOM_tiEngRun: data-element=R_EOM_tiEngRun.EOM_tiEngRun
          dr_VlvSys_agCkOpInVlvReqRef0: data-element=R_VlvSys_agCkOpInVlvReqRef0.VlvSys_agCkOpInVlvReqRef0
        5 x data send point:
          ds_EngM_agCkOpInVlvReqRef1: data-element=P_EngM_agCkOpInVlvReqRef1.EngM_agCkOpInVlvReqRef1
          ds_EngM_agCkClsExVlvReqRef1: data-element=P_EngM_agCkClsExVlvReqRef1.EngM_agCkClsExVlvReqRef1
          ds_EngM_agCkClsInVlvReqRef0: data-element=P_EngM_agCkClsInVlvReqRef0.EngM_agCkClsInVlvReqRef0
          ds_EngM_agCkOpExVlvReqRef0: data-element=P_EngM_agCkOpExVlvReqRef0.EngM_agCkOpExVlvReqRef0
          ds_EngM_agCkOpExVlvReqRef1: data-element=P_EngM_agCkOpExVlvReqRef1.EngM_agCkOpExVlvReqRef1
        sync call ssp_LibVlvBasChg: operation=R_LibVlvBasChg.OP_LibVlvBasChg
      RE_EngMGslT_020_TEV: read-variable=[AirEfc_facChrExpFilPred_irv, AirEfc_facChrExpScvFilPred_irv], written-variable=[EngM_prm_mfAirPredCyl_001_irv, EngM_prm_rAirLdPredCyl_002_irv, EngM_prm_rAirLdPredCyl_003_irv, EngM_prm_mfAirPredCyl_004_irv, EngM_prm_mfAirPredCyl_003_irv, EngM_prm_mAirPredCyl_005_irv, EngM_prm_rAirLdPredCyl_005_irv, EngM_prm_mAirPredCyl_001_irv, AirEfc_facChrExpFilPred_irv, AirEfc_facChrExpScvFilPred_irv, EngM_prm_mfAirPredCyl_006_irv, EngM_prm_mAirPredCyl_002_irv, EngM_prm_rAirLdPredCyl_006_irv, EngM_prm_mAirPredCyl_003_irv, EngM_prm_mAirPredCyl_004_irv, EngM_prm_rAirLdPredCyl_004_irv, EngM_prm_mfAirPredCyl_005_irv, EngM_prm_mAirPredCyl_006_irv, EngM_prm_rAirLdPredCyl_001_irv, EngM_prm_mfAirPredCyl_002_irv]
        28 x data receive point:
          dr_FuSysM_tFu: data-element=R_FuSysM_tFu.FuSysM_tFu
          dr_EngM_agCkOpInVlvEstimRef1: data-element=R_EngM_agCkOpInVlvEstimRef1.EngM_agCkOpInVlvEstimRef1
          dr_Eng_noCmprCyl: data-element=R_Eng_noCmprCyl.Eng_noCmprCyl
          dr_EngM_agCkClsExVlvEstimRef1: data-element=R_EngM_agCkClsExVlvEstimRef1.EngM_agCkClsExVlvEstimRef1
          dr_InjSys_prm_mFuInjH2ReqCyl: data-element=R_InjSys_prm_mFuInjH2ReqCyl.InjSys_prm_mFuInjH2ReqCyl
          dr_FARSp_rMixtCylSp: data-element=R_FARSp_rMixtCylSp.FARSp_rMixtCylSp
          dr_ExM_prm_pExMnfEstimOvlpCyl: data-element=R_ExM_prm_pExMnfEstimOvlpCyl.ExM_prm_pExMnfEstimOvlpCyl
          dr_EngM_facCorOfsEfc: data-element=R_EngM_facCorOfsEfc.EngM_facCorOfsEfc
          dr_Eng_noExNxtCyl: data-element=R_Eng_noExNxtCyl.Eng_noExNxtCyl
          dr_Ext_nEng: data-element=R_Ext_nEng.Ext_nEng
          dr_Eng_noInCyl: data-element=R_Eng_noInCyl.Eng_noInCyl
          dr_InjSys_prm_agEndInjH1ReqCyl: data-element=R_InjSys_prm_agEndInjH1ReqCyl.InjSys_prm_agEndInjH1ReqCyl
          dr_InM_prm_concAirPredCyl: data-element=R_InM_prm_concAirPredCyl.InM_prm_concAirPredCyl
          dr_InM_prm_pDsThrPredCyl: data-element=R_InM_prm_pDsThrPredCyl.InM_prm_pDsThrPredCyl
          dr_UsThrM_pAirExt: data-element=R_UsThrM_pAirExt.UsThrM_pAirExt
          dr_EngM_agCkClsInVlvEstimRef1: data-element=R_EngM_agCkClsInVlvEstimRef1.EngM_agCkClsInVlvEstimRef1
          dr_InjSys_prm_mFuInjH1ReqCyl: data-element=R_InjSys_prm_mFuInjH1ReqCyl.InjSys_prm_mFuInjH1ReqCyl
          dr_InjSys_prm_agBegInjH1ReqCyl: data-element=R_InjSys_prm_agBegInjH1ReqCyl.InjSys_prm_agBegInjH1ReqCyl
          dr_InM_prm_pDsThrPredOvlpCyl: data-element=R_InM_prm_pDsThrPredOvlpCyl.InM_prm_pDsThrPredOvlpCyl
          dr_Ext_tCoMes: data-element=R_Ext_tCoMes.Ext_tCoMes
          dr_Eng_noCmbCyl: data-element=R_Eng_noCmbCyl.Eng_noCmbCyl
          dr_InThM_tAirUsInVlvEstim: data-element=R_InThM_tAirUsInVlvEstim.InThM_tAirUsInVlvEstim
          dr_Eng_noExCyl: data-element=R_Eng_noExCyl.Eng_noExCyl
          dr_InjSys_prm_agEndInjH2ReqCyl: data-element=R_InjSys_prm_agEndInjH2ReqCyl.InjSys_prm_agEndInjH2ReqCyl
          dr_ExM_prm_tExMnfEstimCyl: data-element=R_ExM_prm_tExMnfEstimCyl.ExM_prm_tExMnfEstimCyl
          dr_InjSys_prm_agBegInjH2ReqCyl: data-element=R_InjSys_prm_agBegInjH2ReqCyl.InjSys_prm_agBegInjH2ReqCyl
          dr_InThM_nEngCor: data-element=R_InThM_nEngCor.InThM_nEngCor
          dr_EngM_facCorSlopEfc: data-element=R_EngM_facCorSlopEfc.EngM_facCorSlopEfc
        9 x data send point:
          ds_EngM_rTotLdExPred: data-element=P_EngM_rTotLdExPred.EngM_rTotLdExPred
          ds_EngM_facAPred: data-element=P_EngM_facAPred.EngM_facAPred
          ds_EngM_rAirLdPred: data-element=P_EngM_rAirLdPred.EngM_rAirLdPred
          ds_EngM_facSlopEfcPred: data-element=P_EngM_facSlopEfcPred.EngM_facSlopEfcPred
          ds_EngM_facOfsEfcPred: data-element=P_EngM_facOfsEfcPred.EngM_facOfsEfcPred
          ds_EngM_mfAirPred: data-element=P_EngM_mfAirPred.EngM_mfAirPred
          ds_EngM_mAirPred: data-element=P_EngM_mAirPred.EngM_mAirPred
          ds_EngM_mTotExPred: data-element=P_EngM_mTotExPred.EngM_mTotExPred
          ds_EngM_mfTotExPred: data-element=P_EngM_mfTotExPred.EngM_mfTotExPred
        sync call ssp_LibEngCylPrm: operation=R_LibEngCylPrm.OP_LibEngCylPrm
        sync call ssp_LibAirEfc: operation=R_LibAirEfc.OP_LibAirEfc
      RE_EngMGslT_001_MSE: written-variable=[EngM_agCkClsInVlvReqRef1_irv, EngM_prm_mfAirPredCyl_003_irv, EngM_prm_rAirLdPredCyl_001_irv, EngM_pBegCorBoostSlopEfcPrev_irv, EngM_prm_mAirPredCyl_006_irv, EngM_prm_mAirPredCyl_001_irv, EngM_facTCoPrev_irv, AirEfc_facChrExpFilReq_irv, EngM_rVolCylClsInVlvPrev_irv, InM_pDsThrPrev_irv, EngM_prm_mAirPredCyl_005_irv, AirEfc_facChrExpScvFilCor_irv, EngM_facECor_irv, EngM_prm_mfAirPredCyl_004_irv, EngM_prm_rAirLdPredCyl_005_irv, AirEfc_facChrExpScvFilPred_irv, EngM_rMaxAvlLd_irv, EngM_prm_rAirLdPredCyl_004_irv, EngM_prm_mAirPredCyl_002_irv, EngM_prm_mfAirPredCyl_001_irv, EngM_prm_rAirLdPredCyl_003_irv, AirEfc_facChrExpFilCor_irv, EngM_prm_mAirPredCyl_003_irv, EngM_facCorBoostSlopEfcPrev_irv, EngM_prm_mfAirPredCyl_002_irv, EngM_prm_rAirLdPredCyl_002_irv, EngM_rMinTotLd_irv, EngM_prm_mfAirPredCyl_006_irv, EngM_prm_rAirLdPredCyl_006_irv, AirEfc_facChrExpFilPred_irv, EngM_facCorAtmSlopEfcPrev_irv, AirEfc_facChrExpScvFilReq_irv, EngM_prm_mfAirPredCyl_005_irv, EngM_prm_mAirPredCyl_004_irv, EngM_pDeltaCorSlopEfcPrev_irv, EngM_facTAirUsInVlvPrev_irv]
        64 x data send point:
          ds_EngM_prm_mfAirPredInCyl: data-element=P_EngM_prm_mfAirPredInCyl.EngM_prm_mfAirPredInCyl
          ds_EngM_prm_rAirLdPredInCyl: data-element=P_EngM_prm_rAirLdPredInCyl.EngM_prm_rAirLdPredInCyl
          ds_EngM_mfAirPred: data-element=P_EngM_mfAirPred.EngM_mfAirPred
          ds_EngM_agCkOpExVlvReqRef1: data-element=P_EngM_agCkOpExVlvReqRef1.EngM_agCkOpExVlvReqRef1
          ds_EngM_facOfsEfcPred: data-element=P_EngM_facOfsEfcPred.EngM_facOfsEfcPred
          ds_EngM_agCkOpInVlvReqRef1: data-element=P_EngM_agCkOpInVlvReqRef1.EngM_agCkOpInVlvReqRef1
          ds_EngM_agCkClsInVlvEstimRef0: data-element=P_EngM_agCkClsInVlvEstimRef0.EngM_agCkClsInVlvEstimRef0
          ds_EngM_agCkClsExVlvEstimRef1: data-element=P_EngM_agCkClsExVlvEstimRef1.EngM_agCkClsExVlvEstimRef1
          ds_EngM_facOfsEfcReq: data-element=P_EngM_facOfsEfcReq.EngM_facOfsEfcReq
          ds_EngM_agCkClsInVlvEstimRef1: data-element=P_EngM_agCkClsInVlvEstimRef1.EngM_agCkClsInVlvEstimRef1
          ds_EngM_mfTotExCor: data-element=P_EngM_mfTotExCor.EngM_mfTotExCor
          ds_EngM_mAirEngCylTrbMax: data-element=P_EngM_mAirEngCylTrbMax.EngM_mAirEngCylTrbMax
          ds_EngM_rTotLdExCor: data-element=P_EngM_rTotLdExCor.EngM_rTotLdExCor
          ds_EngM_facMassAirScvCor: data-element=P_EngM_facMassAirScvCor.EngM_facMassAirScvCor
          ds_EngM_facMassFlowLdCor: data-element=P_EngM_facMassFlowLdCor.EngM_facMassFlowLdCor
          ds_EngM_mAirEngCylMin: data-element=P_EngM_mAirEngCylMin.EngM_mAirEngCylMin
          ds_EngM_tMixtCylCor: data-element=P_EngM_tMixtCylCor.EngM_tMixtCylCor
          ds_EngM_mfAirScvCor: data-element=P_EngM_mfAirScvCor.EngM_mfAirScvCor
          ds_EngM_pInMnfMinReq: data-element=P_EngM_pInMnfMinReq.EngM_pInMnfMinReq
          ds_EngM_agCkOpInVlvEstimRef1: data-element=P_EngM_agCkOpInVlvEstimRef1.EngM_agCkOpInVlvEstimRef1
          ds_EngM_prm_mAirScvCorCyl: data-element=P_EngM_prm_mAirScvCorCyl.EngM_prm_mAirScvCorCyl
          ds_EngM_mAirEngCylMax: data-element=P_EngM_mAirEngCylMax.EngM_mAirEngCylMax
          ds_EngM_mAirCor: data-element=P_EngM_mAirCor.EngM_mAirCor
          ds_EngM_facOfsEfcCor: data-element=P_EngM_facOfsEfcCor.EngM_facOfsEfcCor
          ds_EngM_agCkOpExVlvEstimRef1: data-element=P_EngM_agCkOpExVlvEstimRef1.EngM_agCkOpExVlvEstimRef1
          ds_EngM_mBurnCor: data-element=P_EngM_mBurnCor.EngM_mBurnCor
          ds_EngM_rAirLdPred: data-element=P_EngM_rAirLdPred.EngM_rAirLdPred
          ds_EngM_prm_mfAirScvCorCyl: data-element=P_EngM_prm_mfAirScvCorCyl.EngM_prm_mfAirScvCorCyl
          ds_EngM_agCkClsExVlvReqRef1: data-element=P_EngM_agCkClsExVlvReqRef1.EngM_agCkClsExVlvReqRef1
          ds_EngM_facSlopEfcCor: data-element=P_EngM_facSlopEfcCor.EngM_facSlopEfcCor
          ds_EngM_agCkOpExVlvReqRef0: data-element=P_EngM_agCkOpExVlvReqRef0.EngM_agCkOpExVlvReqRef0
          ds_EngM_rltMassAirScvCor: data-element=P_EngM_rltMassAirScvCor.EngM_rltMassAirScvCor
          ds_EngM_facMassAirScvReq: data-element=P_EngM_facMassAirScvReq.EngM_facMassAirScvReq
          ds_EngM_mAirPredIn: data-element=P_EngM_mAirPredIn.EngM_mAirPredIn
          ds_EngM_facDCor: data-element=P_EngM_facDCor.EngM_facDCor
          ds_EngM_mfAirCor: data-element=P_EngM_mfAirCor.EngM_mfAirCor
          ds_EngM_rTotLdExPred: data-element=P_EngM_rTotLdExPred.EngM_rTotLdExPred
          ds_EngM_rDeltaLdInjPha: data-element=P_EngM_rDeltaLdInjPha.EngM_rDeltaLdInjPha
          ds_EngM_facSlopEfcPred: data-element=P_EngM_facSlopEfcPred.EngM_facSlopEfcPred
          ds_EngM_rItBurnRateCor: data-element=P_EngM_rItBurnRateCor.EngM_rItBurnRateCor
          ds_EngM_rMassAirResiCor: data-element=P_EngM_rMassAirResiCor.EngM_rMassAirResiCor
          ds_EngM_prm_mfAirCorCyl: data-element=P_EngM_prm_mfAirCorCyl.EngM_prm_mfAirCorCyl
          ds_EngM_prm_mAirPredInCyl: data-element=P_EngM_prm_mAirPredInCyl.EngM_prm_mAirPredInCyl
          ds_EngM_tBurnCylCor: data-element=P_EngM_tBurnCylCor.EngM_tBurnCylCor
          ds_EngM_mfTotExPredIn: data-element=P_EngM_mfTotExPredIn.EngM_mfTotExPredIn
          ds_EngM_mfTotExPred: data-element=P_EngM_mfTotExPred.EngM_mfTotExPred
          ds_EngM_mTotExPred: data-element=P_EngM_mTotExPred.EngM_mTotExPred
          ds_EngM_rAirLdPredIn: data-element=P_EngM_rAirLdPredIn.EngM_rAirLdPredIn
          ds_EngM_facSlopEfcReq: data-element=P_EngM_facSlopEfcReq.EngM_facSlopEfcReq
          ds_EngM_mAirPresUsThr: data-element=P_EngM_mAirPresUsThr.EngM_mAirPresUsThr
          ds_EngM_rMaxTotLd: data-element=P_EngM_rMaxTotLd.EngM_rMaxTotLd
          ds_EngM_prm_rTotLdExCorCyl: data-element=P_EngM_prm_rTotLdExCorCyl.EngM_prm_rTotLdExCorCyl
          ds_EngM_mAirScvCor: data-element=P_EngM_mAirScvCor.EngM_mAirScvCor
          ds_EngM_facACor: data-element=P_EngM_facACor.EngM_facACor
          ds_EngM_rMassAirScvCor: data-element=P_EngM_rMassAirScvCor.EngM_rMassAirScvCor
          ds_EngM_mAirPred: data-element=P_EngM_mAirPred.EngM_mAirPred
          ds_EngM_mTotExPredIn: data-element=P_EngM_mTotExPredIn.EngM_mTotExPredIn
          ds_EngM_mfAirPredIn: data-element=P_EngM_mfAirPredIn.EngM_mfAirPredIn
          ds_EngM_rAirLdCor: data-element=P_EngM_rAirLdCor.EngM_rAirLdCor
          ds_EngM_agCkOpExVlvEstimRef0: data-element=P_EngM_agCkOpExVlvEstimRef0.EngM_agCkOpExVlvEstimRef0
          ds_EngM_tMixtCylGDICor: data-element=P_EngM_tMixtCylGDICor.EngM_tMixtCylGDICor
          ds_EngM_agCkClsInVlvReqRef0: data-element=P_EngM_agCkClsInVlvReqRef0.EngM_agCkClsInVlvReqRef0
          ds_EngM_facAPred: data-element=P_EngM_facAPred.EngM_facAPred
          ds_EngM_prm_mfTotExCorCyl: data-element=P_EngM_prm_mfTotExCorCyl.EngM_prm_mfTotExCorCyl
      RE_EngMGslT_002_TEV: read-variable=[EngM_prm_mAirPredCyl_002_irv, EngM_prm_mAirPredCyl_006_irv, EngM_prm_rAirLdPredCyl_005_irv, EngM_prm_mAirPredCyl_004_irv, EngM_prm_mfAirPredCyl_003_irv, EngM_prm_mfAirPredCyl_001_irv, EngM_prm_rAirLdPredCyl_006_irv, EngM_prm_mfAirPredCyl_004_irv, EngM_prm_mAirPredCyl_003_irv, EngM_prm_rAirLdPredCyl_001_irv, EngM_prm_rAirLdPredCyl_004_irv, EngM_prm_mAirPredCyl_001_irv, EngM_prm_rAirLdPredCyl_003_irv, EngM_prm_rAirLdPredCyl_002_irv, EngM_prm_mfAirPredCyl_005_irv, EngM_prm_mAirPredCyl_005_irv, EngM_prm_mfAirPredCyl_002_irv, EngM_prm_mfAirPredCyl_006_irv]
        9 x data receive point:
          dr_Eng_noInCyl: data-element=R_Eng_noInCyl.Eng_noInCyl
          dr_EngM_rMassAirResiCor: data-element=R_EngM_rMassAirResiCor.EngM_rMassAirResiCor
          dr_InM_concAirCor: data-element=R_InM_concAirCor.InM_concAirCor
          dr_InM_prm_pDsThrPredCyl: data-element=R_InM_prm_pDsThrPredCyl.InM_prm_pDsThrPredCyl
          dr_EngM_facSlopEfcCor: data-element=R_EngM_facSlopEfcCor.EngM_facSlopEfcCor
          dr_EngM_facOfsEfcCor: data-element=R_EngM_facOfsEfcCor.EngM_facOfsEfcCor
          dr_EngM_rMassAirScvCor: data-element=R_EngM_rMassAirScvCor.EngM_rMassAirScvCor
          dr_Ext_nEng: data-element=R_Ext_nEng.Ext_nEng
          dr_EngM_facMassFlowLdCor: data-element=R_EngM_facMassFlowLdCor.EngM_facMassFlowLdCor
        8 x data send point:
          ds_EngM_rAirLdPredIn: data-element=P_EngM_rAirLdPredIn.EngM_rAirLdPredIn
          ds_EngM_mfAirPredIn: data-element=P_EngM_mfAirPredIn.EngM_mfAirPredIn
          ds_EngM_mfTotExPredIn: data-element=P_EngM_mfTotExPredIn.EngM_mfTotExPredIn
          ds_EngM_prm_rAirLdPredInCyl: data-element=P_EngM_prm_rAirLdPredInCyl.EngM_prm_rAirLdPredInCyl
          ds_EngM_prm_mAirPredInCyl: data-element=P_EngM_prm_mAirPredInCyl.EngM_prm_mAirPredInCyl
          ds_EngM_mTotExPredIn: data-element=P_EngM_mTotExPredIn.EngM_mTotExPredIn
          ds_EngM_mAirPredIn: data-element=P_EngM_mAirPredIn.EngM_mAirPredIn
          ds_EngM_prm_mfAirPredInCyl: data-element=P_EngM_prm_mfAirPredInCyl.EngM_prm_mfAirPredInCyl
      RE_EngMGslT_026_TEV: read-variable=EngM_facECor_irv, written-variable=EngM_rMinTotLd_irv
        13 x data receive point:
          dr_UsThrM_pAirExt: data-element=R_UsThrM_pAirExt.UsThrM_pAirExt
          dr_EngM_facSlopEfcCor: data-element=R_EngM_facSlopEfcCor.EngM_facSlopEfcCor
          dr_Ext_tCoMes: data-element=R_Ext_tCoMes.Ext_tCoMes
          dr_Ext_nEng: data-element=R_Ext_nEng.Ext_nEng
          dr_InjSys_bAcvAirLdMinSat: data-element=R_InjSys_bAcvAirLdMinSat.InjSys_bAcvAirLdMinSat
          dr_Ext_pFuMesFineResl: data-element=R_Ext_pFuMesFineResl.Ext_pFuMesFineResl
          dr_InM_concAirCor: data-element=R_InM_concAirCor.InM_concAirCor
          dr_Ext_bAcvGasMod: data-element=R_Ext_bAcvGasMod.Ext_bAcvGasMod
          dr_EngM_facOfsEfcCor: data-element=R_EngM_facOfsEfcCor.EngM_facOfsEfcCor
          dr_FARSp_rMixtCylSp: data-element=R_FARSp_rMixtCylSp.FARSp_rMixtCylSp
          dr_CanPurg_mfFuStmEstim: data-element=R_CanPurg_mfFuStmEstim.CanPurg_mfFuStmEstim
          dr_EngM_facACor: data-element=R_EngM_facACor.EngM_facACor
          dr_InjSys_prm_bInjCutOffCyl: data-element=R_InjSys_prm_bInjCutOffCyl.InjSys_prm_bInjCutOffCyl
        data send point ds_EngM_pInMnfMinReq: data-element=P_EngM_pInMnfMinReq.EngM_pInMnfMinReq
  swc implementation Imp_EngMGslT: code-generator=Real-Time Workshop Embedded Coder 5.5 (R2010a) 25-Jan-2010, programming-language=C, behavior=IB_EngMGslT
    code-descriptors:
      code CodeDescriptor: type=SRC
        10 x xfile:
          EngMGslT_h: url=EngMGslT.h
          EngMGslT_import_h: url=EngMGslT_import.h
          EngMGslT_data_c: url=EngMGslT_data.c
          EngMGslT_MemMap_h: url=EngMGslT_MemMap.h
          EngMGslT_private_h: url=EngMGslT_private.h
          EngMGslT_types_h: url=EngMGslT_types.h
          EngMGslT_Version_h: url=EngMGslT_Version.h
          EngMGslT_Def_c: url=EngMGslT_Def.c
          EngMGslT_Version_c: url=EngMGslT_Version.c
          EngMGslT_c: url=EngMGslT.c
package /Components/SWC_EngMGslT/EngMGslT_IRVDatatypes
  36 x integer type, all with lower-limit=0:
    DT_AirEfc_facChrExpFilCor_irv: base-type=uint16, upper-limit=65535
    DT_AirEfc_facChrExpFilPred_irv: base-type=uint16, upper-limit=65535
    DT_AirEfc_facChrExpFilReq_irv: base-type=uint16, upper-limit=65535
    DT_AirEfc_facChrExpScvFilCor_irv: base-type=uint16, upper-limit=65535
    DT_AirEfc_facChrExpScvFilPred_irv: base-type=uint16, upper-limit=65535
    DT_AirEfc_facChrExpScvFilReq_irv: base-type=uint16, upper-limit=65535
    DT_EngM_agCkClsInVlvReqRef1_irv: base-type=uint8, upper-limit=255
    DT_EngM_facCorAtmSlopEfcPrev_irv: base-type=uint16, upper-limit=65535
    DT_EngM_facCorBoostSlopEfcPrev_irv: base-type=uint16, upper-limit=65535
    DT_EngM_facECor_irv: base-type=uint16, upper-limit=65535
    DT_EngM_facTAirUsInVlvPrev_irv: base-type=uint16, upper-limit=65535
    DT_EngM_facTCoPrev_irv: base-type=uint8, upper-limit=255
    DT_EngM_pBegCorBoostSlopEfcPrev_irv: base-type=uint16, upper-limit=65535
    DT_EngM_pDeltaCorSlopEfcPrev_irv: base-type=uint16, upper-limit=65535
    DT_EngM_prm_mAirPredCyl_{001..006}_irv: base-type=uint16, upper-limit=65535
    DT_EngM_prm_mfAirPredCyl_{001..006}_irv: base-type=uint16, upper-limit=65535
    DT_EngM_prm_rAirLdPredCyl_{001..006}_irv: base-type=uint16, upper-limit=65535
    DT_EngM_rMaxAvlLd_irv: base-type=uint16, upper-limit=65535
    DT_EngM_rMinTotLd_irv: base-type=uint16, upper-limit=65535
    DT_EngM_rVolCylClsInVlvPrev_irv: base-type=uint16, upper-limit=65535
    DT_InM_pDsThrPrev_irv: base-type=uint16, upper-limit=65535
